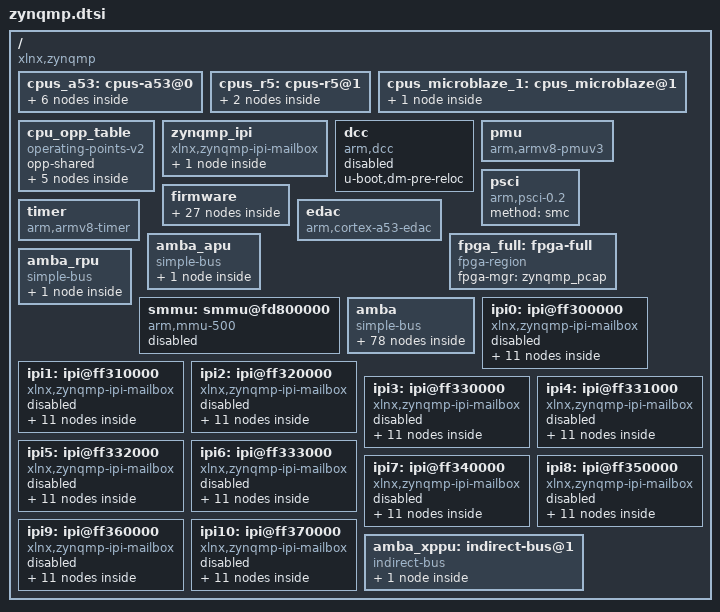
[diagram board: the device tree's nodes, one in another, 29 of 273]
// SPDX-License-Identifier: GPL-2.0+
/*
 * dts file for Xilinx ZynqMP
 *
 * (C) Copyright 2014 - 2021, Xilinx, Inc.
 *
 * Michal Simek <michal.simek@xilinx.com>
 *
 * This program is free software; you can redistribute it and/or
 * modify it under the terms of the GNU General Public License as
 * published by the Free Software Foundation; either version 2 of
 * the License, or (at your option) any later version.
 */

#include "include/dt-bindings/dma/xlnx-zynqmp-dpdma.h"
#include "include/dt-bindings/gpio/gpio.h"
#include "include/dt-bindings/power/xlnx-zynqmp-power.h"
#include "include/dt-bindings/reset/xlnx-zynqmp-resets.h"

/ {
	compatible = "xlnx,zynqmp";
	#address-cells = <2>;
	#size-cells = <2>;

	cpus_a53: cpus-a53@0 {
		#address-cells = <1>;
		#size-cells = <0>;

		a53_cpu0: cpu@0 {
			compatible = "arm,cortex-a53";
			device_type = "cpu";
			enable-method = "psci";
			operating-points-v2 = <&cpu_opp_table>;
			reg = <0x0>;
			cpu-idle-states = <&CPU_SLEEP_0>;
                        power-domains = <&zynqmp_firmware 0x2>;
		};

		a53_cpu1: cpu@1 {
			compatible = "arm,cortex-a53";
			device_type = "cpu";
			enable-method = "psci";
			reg = <0x1>;
			operating-points-v2 = <&cpu_opp_table>;
			cpu-idle-states = <&CPU_SLEEP_0>;
                        power-domains = <&zynqmp_firmware 0x3>;
		};

		a53_cpu2: cpu@2 {
			compatible = "arm,cortex-a53";
			device_type = "cpu";
			enable-method = "psci";
			reg = <0x2>;
			operating-points-v2 = <&cpu_opp_table>;
			cpu-idle-states = <&CPU_SLEEP_0>;
                        power-domains = <&zynqmp_firmware 0x4>;
		};

		a53_cpu3: cpu@3 {
			compatible = "arm,cortex-a53";
			device_type = "cpu";
			enable-method = "psci";
			reg = <0x3>;
			operating-points-v2 = <&cpu_opp_table>;
			cpu-idle-states = <&CPU_SLEEP_0>;
                        power-domains = <&zynqmp_firmware 0x5>;
		};


		idle-states {
			entry-method = "psci";

			CPU_SLEEP_0: cpu-sleep-0 {
				compatible = "arm,idle-state";
				arm,psci-suspend-param = <0x40000000>;
				local-timer-stop;
				entry-latency-us = <300>;
				exit-latency-us = <600>;
				min-residency-us = <10000>;
			};
		};
	};
	cpus_r5: cpus-r5@1 {
		#address-cells = <1>;
		#size-cells = <0>;

		r5_cpu0: cpu@0 {
			compatible = "arm,cortex-r5", "arm,armv8";
			device_type = "cpu";
			reg = <0x4>;
                        power-domains = <&zynqmp_firmware 0x7>;
		};

		r5_cpu1: cpu@1 {
			compatible = "arm,cortex-r5", "arm,armv8";
			device_type = "cpu";
			reg = <0x5>;
                        power-domains = <&zynqmp_firmware 0x8>;
		};
	};
	cpus_microblaze_1: cpus_microblaze@1 {
		#address-cells = <1>;
		#size-cells = <0>;

		ub1_cpu: cpu@0 {
			compatible = "pmu-microblaze";
			device_type = "cpu";
			reg = <0x6>;
			operating-points-v2 = <&cpu_opp_table>;
		};
	};
	cpu_opp_table: cpu_opp_table {
		compatible = "operating-points-v2";
		opp-shared;
		opp00 {
			opp-hz = /bits/ 64 <1199999988>;
			opp-microvolt = <1000000>;
			clock-latency-ns = <500000>;
		};
		opp01 {
			opp-hz = /bits/ 64 <599999994>;
			opp-microvolt = <1000000>;
			clock-latency-ns = <500000>;
		};
		opp02 {
			opp-hz = /bits/ 64 <399999996>;
			opp-microvolt = <1000000>;
			clock-latency-ns = <500000>;
		};
		opp03 {
			opp-hz = /bits/ 64 <299999997>;
			opp-microvolt = <1000000>;
			clock-latency-ns = <500000>;
		};
		opp04 {
			opp-hz = /bits/ 64 <180000000>;
			opp-microvolt = <1000000>;
			clock-latency-ns = <500000>;
		};
	};

	zynqmp_ipi: zynqmp_ipi {
		u-boot,dm-pre-reloc;
		compatible = "xlnx,zynqmp-ipi-mailbox";
		interrupt-parent = <&imux>;
		interrupts = <0 35 4>;
		xlnx,ipi-id = <0>;
		#address-cells = <2>;
		#size-cells = <2>;
		ranges;

		ipi_mailbox_pmu1: mailbox@ff990400 {
			u-boot,dm-pre-reloc;
			reg = <0x0 0xff9905c0 0x0 0x20>,
			      <0x0 0xff9905e0 0x0 0x20>,
			      <0x0 0xff990e80 0x0 0x20>,
			      <0x0 0xff990ea0 0x0 0x20>;
			reg-names = "local_request_region", "local_response_region",
				    "remote_request_region", "remote_response_region";
			#mbox-cells = <1>;
			xlnx,ipi-id = <4>;
		};
	};

	dcc: dcc {
		compatible = "arm,dcc";
		status = "disabled";
		u-boot,dm-pre-reloc;
	};

	pmu {
		compatible = "arm,armv8-pmuv3";
		interrupt-parent = <&imux>;
		interrupts = <0 143 4>,
			     <0 144 4>,
			     <0 145 4>,
			     <0 146 4>;
	};

	psci {
		compatible = "arm,psci-0.2";
		method = "smc";
	};

	firmware {
		zynqmp_firmware: zynqmp-firmware {
			compatible = "xlnx,zynqmp-firmware";
			u-boot,dm-pre-reloc;
			method = "smc";
			#power-domain-cells = <0x1>;

			zynqmp_power: zynqmp-power {
				u-boot,dm-pre-reloc;
				compatible = "xlnx,zynqmp-power";
				interrupt-parent = <&imux>;
				interrupts = <0 35 4>;
				mboxes = <&ipi_mailbox_pmu1 0>,
                                         <&ipi_mailbox_pmu1 1>;
				mbox-names = "tx", "rx";
			};

                       nvmem_firmware {
                               compatible = "xlnx,zynqmp-nvmem-fw";
                               #address-cells = <1>;
                               #size-cells = <1>;

                               soc_revision: soc_revision@0 {
                                       reg = <0x0 0x4>;
                               };
                               /* efuse access */
                               efuse_dna: efuse_dna@c {
                                       reg = <0xc 0xc>;
                               };
                               efuse_usr0: efuse_usr0@20 {
                                       reg = <0x20 0x4>;
                               };
                               efuse_usr1: efuse_usr1@24 {
                                       reg = <0x24 0x4>;
                               };
                               efuse_usr2: efuse_usr2@28 {
                                       reg = <0x28 0x4>;
                               };
                               efuse_usr3: efuse_usr3@2c {
                                       reg = <0x2c 0x4>;
                               };
                               efuse_usr4: efuse_usr4@30 {
                                       reg = <0x30 0x4>;
                               };
                               efuse_usr5: efuse_usr5@34 {
                                       reg = <0x34 0x4>;
                               };
                               efuse_usr6: efuse_usr6@38 {
                                       reg = <0x38 0x4>;
                               };
                               efuse_usr7: efuse_usr7@3c {
                                       reg = <0x3c 0x4>;
                               };
                               efuse_miscusr: efuse_miscusr@40 {
                                       reg = <0x40 0x4>;
                               };
                               efuse_chash: efuse_chash@50 {
                                       reg = <0x50 0x4>;
                               };
                               efuse_pufmisc: efuse_pufmisc@54 {
                                       reg = <0x54 0x4>;
                               };
                               efuse_sec: efuse_sec@58 {
                                       reg = <0x58 0x4>;
                               };
                               efuse_spkid: efuse_spkid@5c {
                                       reg = <0x5c 0x4>;
                               };
                               efuse_ppk0hash: efuse_ppk0hash@a0 {
                                       reg = <0xa0 0x30>;
                               };
                               efuse_ppk1hash: efuse_ppk1hash@d0 {
                                       reg = <0xd0 0x30>;
                               };
                       };

                       zynqmp_pcap: pcap {
                               compatible = "xlnx,zynqmp-pcap-fpga";
                               clock-names = "ref_clk";
                       };

                       xlnx_aes: zynqmp-aes {
                               compatible = "xlnx,zynqmp-aes";
                       };

			zynqmp_reset: reset-controller {
				compatible = "xlnx,zynqmp-reset";
				#reset-cells = <1>;
			};

			pinctrl0: pinctrl {
				compatible = "xlnx,zynqmp-pinctrl";
				status = "disabled";
			};

                       xlnx_keccak_384: sha384 {
                               compatible = "xlnx,zynqmp-keccak-384";
                       };

                       xlnx_rsa: zynqmp-rsa {
                               compatible = "xlnx,zynqmp-rsa";
                       };

                       modepin_gpio: gpio {
                               compatible = "xlnx,zynqmp-gpio-modepin";
                               gpio-controller;
                               #gpio-cells = <2>;
                       };
		};
	};

	timer {
		compatible = "arm,armv8-timer";
		interrupt-parent = <&imux>;
		interrupts = <1 13 0xf08>,
			     <1 14 0xf08>,
			     <1 11 0xf08>,
			     <1 10 0xf08>;
	};

	edac {
		compatible = "arm,cortex-a53-edac";
	};

	fpga_full: fpga-full {
		compatible = "fpga-region";
		fpga-mgr = <&zynqmp_pcap>;
		#address-cells = <2>;
		#size-cells = <2>;
		ranges;
	};


	amba_apu: amba_apu {
		compatible = "simple-bus";
		#address-cells = <2>;
		#size-cells = <1>;
		ranges = <0 0 0 0 0xffffffff>;

		gic_a53: interrupt-controller@f9010000 {
			compatible = "arm,gic-400";
			#interrupt-cells = <3>;
			reg = <0x0 0xf9010000 0x10000>,
			      <0x0 0xf9020000 0x20000>,
			      <0x0 0xf9040000 0x20000>,
			      <0x0 0xf9060000 0x20000>;
			interrupt-controller;
			interrupt-parent = <&gic_a53>;
			interrupts = <1 9 0xf04>;
			status = "disabled";
		};
	};

	amba_rpu: amba_rpu {
		compatible = "simple-bus";
		#address-cells = <2>;
		#size-cells = <1>;
		gic_r5: interrupt-controller@f9000000 {
			compatible = "arm,gic-400";
			#interrupt-cells = <3>;
			reg = <0x0 0xf9000000 0x10000>,
			      <0x0 0xf9001000 0x10000>;
			interrupt-controller;
			interrupt-parent = <&gic_r5>;
			interrupts = <1 9 0xf04>;
			status = "disabled";
		};
	};

	smmu: smmu@fd800000 {
		compatible = "arm,mmu-500";
		reg = <0x0 0xfd800000 0x0 0x20000>;
		#iommu-cells = <1>;
		status = "disabled";
		#global-interrupts = <1>;
		interrupt-parent = <&imux>;
		interrupts = <0 155 4>,
			<0 155 4>, <0 155 4>, <0 155 4>, <0 155 4>,
			<0 155 4>, <0 155 4>, <0 155 4>, <0 155 4>,
			<0 155 4>, <0 155 4>, <0 155 4>, <0 155 4>,
			<0 155 4>, <0 155 4>, <0 155 4>, <0 155 4>;
	};

	amba: amba {
		compatible = "simple-bus";
		u-boot,dm-pre-reloc;
		#address-cells = <2>;
		#size-cells = <2>;
		ranges;
		interrupt-parent = <&imux>;

		/* Proxy Interrupt Controller */
		imux: interrupt-multiplex {
			compatible = "interrupt-multiplex";
			#address-cells = <0x0>;
			#interrupt-cells = <3>;
			interrupt-controller;
			interrupt-parent = <&gic_a53>, <&gic_r5>;
			/* mask for address cells, mask for interrupt cells of the children */
			interrupt-map-mask = <0x0 0xffff 0x0>;
			/* 1:1 mapping of all interrupts to gic_a53 and gic_r5 */
			/* child address cells, child interrupt cells, parent, parent interrupt cells */
			interrupt-map = <0x0 0x17 0x0 &gic_a53 0x0 0x17 0x1>,
			                <0x0 0x18 0x0 &gic_a53 0x0 0x18 0x1>,
			                <0x0 0x7b 0x0 &gic_a53 0x0 0x7b 0x4>,
			                <0x0 0x56 0x0 &gic_a53 0x0 0x56 0x4>,
			                <0x0 0x7c 0x0 &gic_a53 0x0 0x7c 0x4>,
			                <0x0 0x7d 0x0 &gic_a53 0x0 0x7d 0x4>,
			                <0x0 0x7e 0x0 &gic_a53 0x0 0x8e 0x4>,
			                <0x0 0x7f 0x0 &gic_a53 0x0 0x7f 0x4>,
			                <0x0 0x80 0x0 &gic_a53 0x0 0x80 0x4>,
			                <0x0 0x81 0x0 &gic_a53 0x0 0x81 0x4>,
			                <0x0 0x82 0x0 &gic_a53 0x0 0x82 0x4>,
			                <0x0 0x83 0x0 &gic_a53 0x0 0x83 0x4>,
			                <0x0 0x84 0x0 &gic_a53 0x0 0x84 0x4>,
			                <0x0 0x4d 0x0 &gic_a53 0x0 0x4d 0x4>,
			                <0x0 0x4e 0x0 &gic_a53 0x0 0x4e 0x4>,
			                <0x0 0x4f 0x0 &gic_a53 0x0 0x4f 0x4>,
			                <0x0 0x50 0x0 &gic_a53 0x0 0x50 0x4>,
			                <0x0 0x51 0x0 &gic_a53 0x0 0x51 0x4>,
			                <0x0 0x52 0x0 &gic_a53 0x0 0x52 0x4>,
			                <0x0 0x53 0x0 &gic_a53 0x0 0x53 0x4>,
			                <0x0 0x54 0x0 &gic_a53 0x0 0x54 0x4>,
			                <0x0 0x70 0x0 &gic_a53 0x0 0x70 0x4>,
			                <0x0 0xe 0x0 &gic_a53 0x0 0xe 0x4>,
			                <0x0 0x39 0x0 &gic_a53 0x0 0x39 0x4>,
			                <0x0 0x3b 0x0 &gic_a53 0x0 0x3b 0x4>,
			                <0x0 0x3d 0x0 &gic_a53 0x0 0x3d 0x4>,
			                <0x0 0x3f 0x0 &gic_a53 0x0 0x3f 0x4>,
			                <0x0 0x10 0x0 &gic_a53 0x0 0x10 0x4>,
			                <0x0 0x11 0x0 &gic_a53 0x0 0x11 0x4>,
			                <0x0 0x12 0x0 &gic_a53 0x0 0x12 0x4>,
			                <0x0 0xa 0x0 &gic_a53 0x0 0xa 0x4>,
			                <0x0 0x72 0x0 &gic_a53 0x0 0x72 0x4>,
			                <0x0 0x73 0x0 &gic_a53 0x0 0x73 0x4>,
			                <0x0 0x74 0x0 &gic_a53 0x0 0x74 0x1>,
			                <0x0 0x75 0x0 &gic_a53 0x0 0x75 0x1>,
			                <0x0 0x76 0x0 &gic_a53 0x0 0x76 0x4>,
			                <0x0 0xf 0x0 &gic_a53 0x0 0xf 0x4>,
			                <0x0 0x1a 0x0 &gic_a53 0x0 0x1a 0x4>,
			                <0x0 0x1b 0x0 &gic_a53 0x0 0x1b 0x4>,
			                <0x0 0x85 0x0 &gic_a53 0x0 0x85 0x4>,
			                <0x0 0x30 0x0 &gic_a53 0x0 0x30 0x4>,
			                <0x0 0x31 0x0 &gic_a53 0x0 0x31 0x4>,
			                <0x0 0x13 0x0 &gic_a53 0x0 0x13 0x4>,
			                <0x0 0x14 0x0 &gic_a53 0x0 0x14 0x4>,
			                <0x0 0x24 0x0 &gic_a53 0x0 0x24 0x4>,
			                <0x0 0x25 0x0 &gic_a53 0x0 0x25 0x4>,
			                <0x0 0x26 0x0 &gic_a53 0x0 0x26 0x4>,
			                <0x0 0x27 0x0 &gic_a53 0x0 0x27 0x4>,
			                <0x0 0x28 0x0 &gic_a53 0x0 0x28 0x4>,
			                <0x0 0x29 0x0 &gic_a53 0x0 0x29 0x4>,
			                <0x0 0x2a 0x0 &gic_a53 0x0 0x2a 0x4>,
			                <0x0 0x2b 0x0 &gic_a53 0x0 0x2b 0x4>,
			                <0x0 0x2c 0x0 &gic_a53 0x0 0x2c 0x4>,
			                <0x0 0x2d 0x0 &gic_a53 0x0 0x2d 0x4>,
			                <0x0 0x2e 0x0 &gic_a53 0x0 0x2e 0x4>,
			                <0x0 0x2f 0x0 &gic_a53 0x0 0x2f 0x4>,
			                <0x0 0x15 0x0 &gic_a53 0x0 0x15 0x4>,
			                <0x0 0x16 0x0 &gic_a53 0x0 0x16 0x4>,
			                <0x0 0x41 0x0 &gic_a53 0x0 0x41 0x4>,
			                <0x0 0x45 0x0 &gic_a53 0x0 0x45 0x4>,
			                <0x0 0x4b 0x0 &gic_a53 0x0 0x4b 0x4>,
			                <0x0 0x46 0x0 &gic_a53 0x0 0x46 0x4>,
			                <0x0 0x4a 0x0 &gic_a53 0x0 0x4a 0x4>,
			                <0x0 0x4c 0x0 &gic_a53 0x0 0x4c 0x4>,
			                <0x0 0x35 0x0 &gic_a53 0x0 0x35 0x4>,
			                <0x0 0x71 0x0 &gic_a53 0x0 0x71 0x4>,
			                <0x0 0x77 0x0 &gic_a53 0x0 0x77 0x4>,
			                <0x0 0x1d 0x0 &gic_a53 0x0 0x1d 0x4>,
			                <0x0 0x1e 0x0 &gic_a53 0x0 0x1e 0x4>,
			                <0x0 0x1f 0x0 &gic_a53 0x0 0x1f 0x4>,
			                <0x0 0x20 0x0 &gic_a53 0x0 0x20 0x4>,
			                <0x0 0x21 0x0 &gic_a53 0x0 0x21 0x4>,
			                <0x0 0x22 0x0 &gic_a53 0x0 0x22 0x4>,
			                <0x0 0x23 0x0 &gic_a53 0x0 0x23 0x4>,
			                <0x0 0x7a 0x0 &gic_a53 0x0 0x7a 0x4>,
					<0x0 0x17 0x0 &gic_r5 0x0 0x17 0x1>,
			                <0x0 0x18 0x0 &gic_r5 0x0 0x18 0x1>,
			                <0x0 0x7b 0x0 &gic_r5 0x0 0x7b 0x4>,
			                <0x0 0x56 0x0 &gic_r5 0x0 0x56 0x4>,
			                <0x0 0x7c 0x0 &gic_r5 0x0 0x7c 0x4>,
			                <0x0 0x7d 0x0 &gic_r5 0x0 0x7d 0x4>,
			                <0x0 0x7e 0x0 &gic_r5 0x0 0x8e 0x4>,
			                <0x0 0x7f 0x0 &gic_r5 0x0 0x7f 0x4>,
			                <0x0 0x80 0x0 &gic_r5 0x0 0x80 0x4>,
			                <0x0 0x81 0x0 &gic_r5 0x0 0x81 0x4>,
			                <0x0 0x82 0x0 &gic_r5 0x0 0x82 0x4>,
			                <0x0 0x83 0x0 &gic_r5 0x0 0x83 0x4>,
			                <0x0 0x84 0x0 &gic_r5 0x0 0x84 0x4>,
			                <0x0 0x4d 0x0 &gic_r5 0x0 0x4d 0x4>,
			                <0x0 0x4e 0x0 &gic_r5 0x0 0x4e 0x4>,
			                <0x0 0x4f 0x0 &gic_r5 0x0 0x4f 0x4>,
			                <0x0 0x50 0x0 &gic_r5 0x0 0x50 0x4>,
			                <0x0 0x51 0x0 &gic_r5 0x0 0x51 0x4>,
			                <0x0 0x52 0x0 &gic_r5 0x0 0x52 0x4>,
			                <0x0 0x53 0x0 &gic_r5 0x0 0x53 0x4>,
			                <0x0 0x54 0x0 &gic_r5 0x0 0x54 0x4>,
			                <0x0 0x70 0x0 &gic_r5 0x0 0x70 0x4>,
			                <0x0 0xe 0x0 &gic_r5 0x0 0xe 0x4>,
			                <0x0 0x39 0x0 &gic_r5 0x0 0x39 0x4>,
			                <0x0 0x3b 0x0 &gic_r5 0x0 0x3b 0x4>,
			                <0x0 0x3d 0x0 &gic_r5 0x0 0x3d 0x4>,
			                <0x0 0x3f 0x0 &gic_r5 0x0 0x3f 0x4>,
			                <0x0 0x10 0x0 &gic_r5 0x0 0x10 0x4>,
			                <0x0 0x11 0x0 &gic_r5 0x0 0x11 0x4>,
			                <0x0 0x12 0x0 &gic_r5 0x0 0x12 0x4>,
			                <0x0 0xa 0x0 &gic_r5 0x0 0xa 0x4>,
			                <0x0 0x72 0x0 &gic_r5 0x0 0x72 0x4>,
			                <0x0 0x73 0x0 &gic_r5 0x0 0x73 0x4>,
			                <0x0 0x74 0x0 &gic_r5 0x0 0x74 0x1>,
			                <0x0 0x75 0x0 &gic_r5 0x0 0x75 0x1>,
			                <0x0 0x76 0x0 &gic_r5 0x0 0x76 0x4>,
			                <0x0 0xf 0x0 &gic_r5 0x0 0xf 0x4>,
			                <0x0 0x1a 0x0 &gic_r5 0x0 0x1a 0x4>,
			                <0x0 0x1b 0x0 &gic_r5 0x0 0x1b 0x4>,
			                <0x0 0x85 0x0 &gic_r5 0x0 0x85 0x4>,
			                <0x0 0x30 0x0 &gic_r5 0x0 0x30 0x4>,
			                <0x0 0x31 0x0 &gic_r5 0x0 0x31 0x4>,
			                <0x0 0x13 0x0 &gic_r5 0x0 0x13 0x4>,
			                <0x0 0x14 0x0 &gic_r5 0x0 0x14 0x4>,
			                <0x0 0x24 0x0 &gic_r5 0x0 0x24 0x4>,
			                <0x0 0x25 0x0 &gic_r5 0x0 0x25 0x4>,
			                <0x0 0x26 0x0 &gic_r5 0x0 0x26 0x4>,
			                <0x0 0x27 0x0 &gic_r5 0x0 0x27 0x4>,
			                <0x0 0x28 0x0 &gic_r5 0x0 0x28 0x4>,
			                <0x0 0x29 0x0 &gic_r5 0x0 0x29 0x4>,
			                <0x0 0x2a 0x0 &gic_r5 0x0 0x2a 0x4>,
			                <0x0 0x2b 0x0 &gic_r5 0x0 0x2b 0x4>,
			                <0x0 0x2c 0x0 &gic_r5 0x0 0x2c 0x4>,
			                <0x0 0x2d 0x0 &gic_r5 0x0 0x2d 0x4>,
			                <0x0 0x2e 0x0 &gic_r5 0x0 0x2e 0x4>,
			                <0x0 0x2f 0x0 &gic_r5 0x0 0x2f 0x4>,
			                <0x0 0x15 0x0 &gic_r5 0x0 0x15 0x4>,
			                <0x0 0x16 0x0 &gic_r5 0x0 0x16 0x4>,
			                <0x0 0x41 0x0 &gic_r5 0x0 0x41 0x4>,
			                <0x0 0x45 0x0 &gic_r5 0x0 0x45 0x4>,
			                <0x0 0x4b 0x0 &gic_r5 0x0 0x4b 0x4>,
			                <0x0 0x46 0x0 &gic_r5 0x0 0x46 0x4>,
			                <0x0 0x4a 0x0 &gic_r5 0x0 0x4a 0x4>,
			                <0x0 0x4c 0x0 &gic_r5 0x0 0x4c 0x4>,
			                <0x0 0x35 0x0 &gic_r5 0x0 0x35 0x4>,
			                <0x0 0x71 0x0 &gic_r5 0x0 0x71 0x4>,
			                <0x0 0x77 0x0 &gic_r5 0x0 0x77 0x4>,
			                <0x0 0x1d 0x0 &gic_r5 0x0 0x1d 0x4>,
			                <0x0 0x1e 0x0 &gic_r5 0x0 0x1e 0x4>,
			                <0x0 0x1f 0x0 &gic_r5 0x0 0x1f 0x4>,
			                <0x0 0x20 0x0 &gic_r5 0x0 0x20 0x4>,
			                <0x0 0x21 0x0 &gic_r5 0x0 0x21 0x4>,
			                <0x0 0x22 0x0 &gic_r5 0x0 0x22 0x4>,
			                <0x0 0x23 0x0 &gic_r5 0x0 0x23 0x4>,
			                <0x0 0x7a 0x0 &gic_r5 0x0 0x7a 0x4>;

		};

		can0: can@ff060000 {
			compatible = "xlnx,zynq-can-1.0";
			status = "disabled";
			clock-names = "can_clk", "pclk";
			reg = <0x0 0xff060000 0x0 0x1000>;
			interrupts = <0 23 4>;
			interrupt-parent = <&imux>;
			tx-fifo-depth = <0x40>;
			rx-fifo-depth = <0x40>;
			power-domains = <&zynqmp_firmware 47>;
		};

		can1: can@ff070000 {
			compatible = "xlnx,zynq-can-1.0";
			status = "disabled";
			clock-names = "can_clk", "pclk";
			reg = <0x0 0xff070000 0x0 0x1000>;
			interrupts = <0 24 4>;
			interrupt-parent = <&imux>;
			tx-fifo-depth = <0x40>;
			rx-fifo-depth = <0x40>;
			power-domains = <&zynqmp_firmware 48>;
		};

		cci: cci@fd6e0000 {
			compatible = "arm,cci-400";
			reg = <0x0 0xfd6e0000 0x0 0x9000>;
			ranges = <0x0 0x0 0xfd6e0000 0x10000>;
			#address-cells = <1>;
			#size-cells = <1>;
			status = "disabled";

			pmu@9000 {
				compatible = "arm,cci-400-pmu,r1";
				reg = <0x9000 0x5000>;
				interrupt-parent = <&imux>;
				interrupts = <0 123 4>,
					     <0 123 4>,
					     <0 123 4>,
					     <0 123 4>,
					     <0 123 4>;
			};
		};

		/* GDMA */
		fpd_dma_chan1: dma-controller@fd500000 {
			status = "disabled";
			compatible = "xlnx,zynqmp-dma-1.0";
			reg = <0x0 0xfd500000 0x0 0x1000>;
			interrupt-parent = <&imux>;
			interrupts = <0 124 4>;
			clock-names = "clk_main", "clk_apb";
			xlnx,bus-width = <128>;
			#stream-id-cells = <1>;
			iommus = <&smmu 0x14e8>;
			power-domains = <&zynqmp_firmware 42>;
			#dma-cells = <1>;
		};

		fpd_dma_chan2: dma-controller@fd510000 {
			status = "disabled";
			compatible = "xlnx,zynqmp-dma-1.0";
			reg = <0x0 0xfd510000 0x0 0x1000>;
			interrupt-parent = <&imux>;
			interrupts = <0 125 4>;
			clock-names = "clk_main", "clk_apb";
			xlnx,bus-width = <128>;
			#stream-id-cells = <1>;
			iommus = <&smmu 0x14e9>;
			power-domains = <&zynqmp_firmware 42>;
			#dma-cells = <1>;
		};

		fpd_dma_chan3: dma-controller@fd520000 {
			status = "disabled";
			compatible = "xlnx,zynqmp-dma-1.0";
			reg = <0x0 0xfd520000 0x0 0x1000>;
			interrupt-parent = <&imux>;
			interrupts = <0 126 4>;
			clock-names = "clk_main", "clk_apb";
			xlnx,bus-width = <128>;
			#stream-id-cells = <1>;
			iommus = <&smmu 0x14ea>;
			power-domains = <&zynqmp_firmware 42>;
			#dma-cells = <1>;
		};

		fpd_dma_chan4: dma-controller@fd530000 {
			status = "disabled";
			compatible = "xlnx,zynqmp-dma-1.0";
			reg = <0x0 0xfd530000 0x0 0x1000>;
			interrupt-parent = <&imux>;
			interrupts = <0 127 4>;
			clock-names = "clk_main", "clk_apb";
			xlnx,bus-width = <128>;
			#stream-id-cells = <1>;
			iommus = <&smmu 0x14eb>;
			power-domains = <&zynqmp_firmware 42>;
			#dma-cells = <1>;
		};

		fpd_dma_chan5: dma-controller@fd540000 {
			status = "disabled";
			compatible = "xlnx,zynqmp-dma-1.0";
			reg = <0x0 0xfd540000 0x0 0x1000>;
			interrupt-parent = <&imux>;
			interrupts = <0 128 4>;
			clock-names = "clk_main", "clk_apb";
			xlnx,bus-width = <128>;
			#stream-id-cells = <1>;
			iommus = <&smmu 0x14ec>;
			power-domains = <&zynqmp_firmware 42>;
			#dma-cells = <1>;
		};

		fpd_dma_chan6: dma-controller@fd550000 {
			status = "disabled";
			compatible = "xlnx,zynqmp-dma-1.0";
			reg = <0x0 0xfd550000 0x0 0x1000>;
			interrupt-parent = <&imux>;
			interrupts = <0 129 4>;
			clock-names = "clk_main", "clk_apb";
			xlnx,bus-width = <128>;
			#stream-id-cells = <1>;
			iommus = <&smmu 0x14ed>;
			power-domains = <&zynqmp_firmware 42>;
			#dma-cells = <1>;
		};

		fpd_dma_chan7: dma-controller@fd560000 {
			status = "disabled";
			compatible = "xlnx,zynqmp-dma-1.0";
			reg = <0x0 0xfd560000 0x0 0x1000>;
			interrupt-parent = <&imux>;
			interrupts = <0 130 4>;
			clock-names = "clk_main", "clk_apb";
			xlnx,bus-width = <128>;
			#stream-id-cells = <1>;
			iommus = <&smmu 0x14ee>;
			power-domains = <&zynqmp_firmware 42>;
			#dma-cells = <1>;
		};

		fpd_dma_chan8: dma-controller@fd570000 {
			status = "disabled";
			compatible = "xlnx,zynqmp-dma-1.0";
			reg = <0x0 0xfd570000 0x0 0x1000>;
			interrupt-parent = <&imux>;
			interrupts = <0 131 4>;
			clock-names = "clk_main", "clk_apb";
			xlnx,bus-width = <128>;
			#stream-id-cells = <1>;
			iommus = <&smmu 0x14ef>;
			power-domains = <&zynqmp_firmware 42>;
			#dma-cells = <1>;
		};

		gpu: gpu@fd4b0000 {
			status = "disabled";
			compatible = "arm,mali-400", "arm,mali-utgard";
			reg = <0x0 0xfd4b0000 0x0 0x10000>;
			interrupt-parent = <&imux>;
			interrupts = <0 132 4>, <0 132 4>, <0 132 4>, <0 132 4>, <0 132 4>, <0 132 4>;
			interrupt-names = "IRQGP", "IRQGPMMU", "IRQPP0", "IRQPPMMU0", "IRQPP1", "IRQPPMMU1";
			clock-names = "gpu", "gpu_pp0", "gpu_pp1";
			power-domains = <&zynqmp_firmware 58>;
		};

		/* LPDDMA default allows only secured access. inorder to enable
		 * These dma channels, Users should ensure that these dma
		 * Channels are allowed for non secure access.
		 */
		lpd_dma_chan1: dma-controller@ffa80000 {
			status = "disabled";
			compatible = "xlnx,zynqmp-dma-1.0";
			reg = <0x0 0xffa80000 0x0 0x1000>;
			interrupt-parent = <&imux>;
			interrupts = <0 77 4>;
			clock-names = "clk_main", "clk_apb";
			xlnx,bus-width = <64>;
			#stream-id-cells = <1>;
		/*	iommus = <&smmu 0x868>; */
			power-domains = <&zynqmp_firmware 43>;
			#dma-cells = <1>;
		};

		lpd_dma_chan2: dma-controller@ffa90000 {
			status = "disabled";
			compatible = "xlnx,zynqmp-dma-1.0";
			reg = <0x0 0xffa90000 0x0 0x1000>;
			interrupt-parent = <&imux>;
			interrupts = <0 78 4>;
			clock-names = "clk_main", "clk_apb";
			xlnx,bus-width = <64>;
			#stream-id-cells = <1>;
		/*	iommus = <&smmu 0x869>; */
			power-domains = <&zynqmp_firmware 43>;
			#dma-cells = <1>;
		};

		lpd_dma_chan3: dma-controller@ffaa0000 {
			status = "disabled";
			compatible = "xlnx,zynqmp-dma-1.0";
			reg = <0x0 0xffaa0000 0x0 0x1000>;
			interrupt-parent = <&imux>;
			interrupts = <0 79 4>;
			clock-names = "clk_main", "clk_apb";
			xlnx,bus-width = <64>;
			#stream-id-cells = <1>;
		/*	iommus = <&smmu 0x86a>; */
			power-domains = <&zynqmp_firmware 43>;
			#dma-cells = <1>;
		};

		lpd_dma_chan4: dma-controller@ffab0000 {
			status = "disabled";
			compatible = "xlnx,zynqmp-dma-1.0";
			reg = <0x0 0xffab0000 0x0 0x1000>;
			interrupt-parent = <&imux>;
			interrupts = <0 80 4>;
			clock-names = "clk_main", "clk_apb";
			xlnx,bus-width = <64>;
			#stream-id-cells = <1>;
		/*	iommus = <&smmu 0x86b>; */
			power-domains = <&zynqmp_firmware 43>;
			#dma-cells = <1>;
		};

		lpd_dma_chan5: dma-controller@ffac0000 {
			status = "disabled";
			compatible = "xlnx,zynqmp-dma-1.0";
			reg = <0x0 0xffac0000 0x0 0x1000>;
			interrupt-parent = <&imux>;
			interrupts = <0 81 4>;
			clock-names = "clk_main", "clk_apb";
			xlnx,bus-width = <64>;
			#stream-id-cells = <1>;
		/*	iommus = <&smmu 0x86c>; */
			power-domains = <&zynqmp_firmware 43>;
			#dma-cells = <1>;
		};

		lpd_dma_chan6: dma-controller@ffad0000 {
			status = "disabled";
			compatible = "xlnx,zynqmp-dma-1.0";
			reg = <0x0 0xffad0000 0x0 0x1000>;
			interrupt-parent = <&imux>;
			interrupts = <0 82 4>;
			clock-names = "clk_main", "clk_apb";
			xlnx,bus-width = <64>;
			#stream-id-cells = <1>;
		/*	iommus = <&smmu 0x86d>; */
			power-domains = <&zynqmp_firmware 43>;
			#dma-cells = <1>;
		};

		lpd_dma_chan7: dma-controller@ffae0000 {
			status = "disabled";
			compatible = "xlnx,zynqmp-dma-1.0";
			reg = <0x0 0xffae0000 0x0 0x1000>;
			interrupt-parent = <&imux>;
			interrupts = <0 83 4>;
			clock-names = "clk_main", "clk_apb";
			xlnx,bus-width = <64>;
			#stream-id-cells = <1>;
		/*	iommus = <&smmu 0x86e>; */
			power-domains = <&zynqmp_firmware 43>;
			#dma-cells = <1>;
		};

		lpd_dma_chan8: dma-controller@ffaf0000 {
			status = "disabled";
			compatible = "xlnx,zynqmp-dma-1.0";
			reg = <0x0 0xffaf0000 0x0 0x1000>;
			interrupt-parent = <&imux>;
			interrupts = <0 84 4>;
			clock-names = "clk_main", "clk_apb";
			xlnx,bus-width = <64>;
			#stream-id-cells = <1>;
		/*	iommus = <&smmu 0x86f>; */
			power-domains = <&zynqmp_firmware 43>;
			#dma-cells = <1>;
		};

		mc: memory-controller@fd070000 {
			compatible = "xlnx,zynqmp-ddrc-2.40a";
			reg = <0x0 0xfd070000 0x0 0x30000>;
			interrupt-parent = <&imux>;
			interrupts = <0 112 4>;
			status = "disabled";
		};

		nand0: nand-controller@ff100000 {
			compatible = "xlnx,zynqmp-nand-controller", "arasan,nfc-v3p10";
			status = "disabled";
			reg = <0x0 0xff100000 0x0 0x1000>;
			clock-names = "controller", "bus";
			interrupt-parent = <&imux>;
			interrupts = <0 14 4>;
			#address-cells = <1>;
			#size-cells = <0>;
			#stream-id-cells = <1>;
			iommus = <&smmu 0x872>;
			power-domains = <&zynqmp_firmware 44>;
		};

		gem0: ethernet@ff0b0000 {
			compatible = "cdns,zynqmp-gem", "cdns,gem";
			status = "disabled";
			interrupt-parent = <&imux>;
			interrupts = <0 57 4>, <0 57 4>;
			reg = <0x0 0xff0b0000 0x0 0x1000>;
			clock-names = "pclk", "hclk", "tx_clk", "rx_clk", "tsu_clk";
			#address-cells = <1>;
			#size-cells = <0>;
			#stream-id-cells = <1>;
			iommus = <&smmu 0x874>;
			power-domains = <&zynqmp_firmware 29>;
			resets = <&zynqmp_reset ZYNQMP_RESET_GEM0>;
		};

		gem1: ethernet@ff0c0000 {
			compatible = "cdns,zynqmp-gem", "cdns,gem";
			status = "disabled";
			interrupt-parent = <&imux>;
			interrupts = <0 59 4>, <0 59 4>;
			reg = <0x0 0xff0c0000 0x0 0x1000>;
			clock-names = "pclk", "hclk", "tx_clk","rx_clk", "tsu_clk";
			#address-cells = <1>;
			#size-cells = <0>;
			#stream-id-cells = <1>;
			iommus = <&smmu 0x875>;
			power-domains = <&zynqmp_firmware 30>;
			resets = <&zynqmp_reset ZYNQMP_RESET_GEM1>;
		};

		gem2: ethernet@ff0d0000 {
			compatible = "cdns,zynqmp-gem", "cdns,gem";
			status = "disabled";
			interrupt-parent = <&imux>;
			interrupts = <0 61 4>, <0 61 4>;
			reg = <0x0 0xff0d0000 0x0 0x1000>;
			clock-names = "pclk", "hclk", "tx_clk","rx_clk", "tsu_clk";
			#address-cells = <1>;
			#size-cells = <0>;
			#stream-id-cells = <1>;
			iommus = <&smmu 0x876>;
			power-domains = <&zynqmp_firmware 31>;
			resets = <&zynqmp_reset ZYNQMP_RESET_GEM2>;
		};

		gem3: ethernet@ff0e0000 {
			compatible = "cdns,zynqmp-gem", "cdns,gem";
			status = "disabled";
			interrupt-parent = <&imux>;
			interrupts = <0 63 4>, <0 63 4>;
			reg = <0x0 0xff0e0000 0x0 0x1000>;
			clock-names = "pclk", "hclk", "tx_clk", "rx_clk", "tsu_clk";
			#address-cells = <1>;
			#size-cells = <0>;
			#stream-id-cells = <1>;
			iommus = <&smmu 0x877>;
			power-domains = <&zynqmp_firmware 32>;
			resets = <&zynqmp_reset ZYNQMP_RESET_GEM3>;
		};

		gpio: gpio@ff0a0000 {
			compatible = "xlnx,zynqmp-gpio-1.0";
			status = "disabled";
			#gpio-cells = <0x2>;
			gpio-controller;
			interrupt-parent = <&imux>;
			interrupts = <0 16 4>;
			interrupt-controller;
			#interrupt-cells = <2>;
			reg = <0x0 0xff0a0000 0x0 0x1000>;
			power-domains = <&zynqmp_firmware 46>;
			calibration = <0x7FFF>;
		};

		i2c0: i2c@ff020000 {
			compatible = "cdns,i2c-r1p14";
			status = "disabled";
			interrupt-parent = <&imux>;
			interrupts = <0 17 4>;
			reg = <0x0 0xff020000 0x0 0x1000>;
			#address-cells = <1>;
			#size-cells = <0>;
			power-domains = <&zynqmp_firmware 37>;
		};

		i2c1: i2c@ff030000 {
			compatible = "cdns,i2c-r1p14";
			status = "disabled";
			interrupt-parent = <&imux>;
			interrupts = <0 18 4>;
			reg = <0x0 0xff030000 0x0 0x1000>;
			#address-cells = <1>;
			#size-cells = <0>;
			power-domains = <&zynqmp_firmware 38>;
		};

		ocm: memory-controller@ff960000 {
			compatible = "xlnx,zynqmp-ocmc-1.0";
			reg = <0x0 0xff960000 0x0 0x1000>;
			interrupt-parent = <&imux>;
			interrupts = <0 10 4>;
		};

		perf_monitor_ocm: perf-monitor@ffa00000 {
			compatible = "xlnx,axi-perf-monitor";
			reg = <0x0 0xffa00000 0x0 0x10000>;
			status = "disabled";
			interrupts = <0 25 4>;
			interrupt-parent = <&imux>;
			xlnx,enable-profile = <0>;
			xlnx,enable-trace = <0>;
			xlnx,num-monitor-slots = <1>;
			xlnx,enable-event-count = <1>;
			xlnx,enable-event-log = <1>;
			xlnx,have-sampled-metric-cnt = <1>;
			xlnx,num-of-counters = <8>;
			xlnx,metric-count-width = <32>;
			xlnx,metrics-sample-count-width = <32>;
			xlnx,global-count-width = <32>;
			xlnx,metric-count-scale = <1>;
		};

		perf_monitor_ddr: perf-monitor@fd0b0000 {
			compatible = "xlnx,axi-perf-monitor";
			reg = <0x0 0xfd0b0000 0x0 0x10000>;
			status = "disabled";
			interrupts = <0 123 4>;
			interrupt-parent = <&imux>;
			xlnx,enable-profile = <0>;
			xlnx,enable-trace = <0>;
			xlnx,num-monitor-slots = <6>;
			xlnx,enable-event-count = <1>;
			xlnx,enable-event-log = <0>;
			xlnx,have-sampled-metric-cnt = <1>;
			xlnx,num-of-counters = <10>;
			xlnx,metric-count-width = <32>;
			xlnx,metrics-sample-count-width = <32>;
			xlnx,global-count-width = <32>;
			xlnx,metric-count-scale = <1>;
		};

		perf_monitor_cci: perf-monitor@fd490000 {
			compatible = "xlnx,axi-perf-monitor";
			reg = <0x0 0xfd490000 0x0 0x10000>;
			status = "disabled";
			interrupts = <0 123 4>;
			interrupt-parent = <&imux>;
			xlnx,enable-profile = <0>;
			xlnx,enable-trace = <0>;
			xlnx,num-monitor-slots = <1>;
			xlnx,enable-event-count = <1>;
			xlnx,enable-event-log = <0>;
			xlnx,have-sampled-metric-cnt = <1>;
			xlnx,num-of-counters = <8>;
			xlnx,metric-count-width = <32>;
			xlnx,metrics-sample-count-width = <32>;
			xlnx,global-count-width = <32>;
			xlnx,metric-count-scale = <1>;
		};

		perf_monitor_lpd: perf-monitor@ffa10000 {
			compatible = "xlnx,axi-perf-monitor";
			reg = <0x0 0xffa10000 0x0 0x10000>;
			status = "disabled";
			interrupts = <0 25 4>;
			interrupt-parent = <&imux>;
			xlnx,enable-profile = <0>;
			xlnx,enable-trace = <0>;
			xlnx,num-monitor-slots = <1>;
			xlnx,enable-event-count = <1>;
			xlnx,enable-event-log = <1>;
			xlnx,have-sampled-metric-cnt = <1>;
			xlnx,num-of-counters = <8>;
			xlnx,metric-count-width = <32>;
			xlnx,metrics-sample-count-width = <32>;
			xlnx,global-count-width = <32>;
			xlnx,metric-count-scale = <1>;
		};

		pcie: pcie@fd0e0000 {
			compatible = "xlnx,nwl-pcie-2.11";
			status = "disabled";
			#address-cells = <3>;
			#size-cells = <2>;
			#interrupt-cells = <1>;
			msi-controller;
			device_type = "pci";
			interrupt-parent = <&imux>;
			interrupts = <0 118 4>,
				     <0 117 4>,
				     <0 116 4>,
				     <0 115 4>,	/* MSI_1 [63...32] */
				     <0 114 4>;	/* MSI_0 [31...0] */
			interrupt-names = "misc", "dummy", "intx",
					  "msi1", "msi0";
			msi-parent = <&pcie>;
			reg = <0x0 0xfd0e0000 0x0 0x1000>,
			      <0x0 0xfd480000 0x0 0x1000>,
			      <0x80 0x00000000 0x0 0x1000000>;
			reg-names = "breg", "pcireg", "cfg";
			ranges = <0x02000000 0x00000000 0xe0000000 0x00000000 0xe0000000 0x00000000 0x10000000	/* non-prefetchable memory */
				  0x43000000 0x00000006 0x00000000 0x00000006 0x00000000 0x00000002 0x00000000>;/* prefetchable memory */
			interrupt-map-mask = <0x0 0x0 0x0 0x7>;
			bus-range = <0x00 0xff>;
			interrupt-map = <0x0 0x0 0x0 0x1 &pcie_intc 0x1>,
					<0x0 0x0 0x0 0x2 &pcie_intc 0x2>,
					<0x0 0x0 0x0 0x3 &pcie_intc 0x3>,
					<0x0 0x0 0x0 0x4 &pcie_intc 0x4>;
			power-domains = <&zynqmp_firmware 59>;
			#stream-id-cells = <1>;
			iommus = <&smmu 0x4d0>;
			pcie_intc: legacy-interrupt-controller {
				interrupt-controller;
				#address-cells = <0>;
				#interrupt-cells = <1>;
			};
		};

		qspi: spi@ff0f0000 {
			u-boot,dm-pre-reloc;
			compatible = "xlnx,zynqmp-qspi-1.0";
			status = "disabled";
			clock-names = "ref_clk", "pclk";
			interrupts = <0 15 4>;
			interrupt-parent = <&imux>;
			num-cs = <1>;
			reg = <0x0 0xff0f0000 0x0 0x1000>,
			      <0x0 0xc0000000 0x0 0x8000000>;
			#address-cells = <1>;
			#size-cells = <0>;
			#stream-id-cells = <1>;
			iommus = <&smmu 0x873>;
			power-domains = <&zynqmp_firmware 45>;
		};

               psgtr: phy@fd400000 {
                       compatible = "xlnx,zynqmp-psgtr-v1.1";
                       status = "disabled";
                       reg = <0x0 0xfd400000 0x0 0x40000>,
                             <0x0 0xfd3d0000 0x0 0x1000>;
                       reg-names = "serdes", "siou";
                       #phy-cells = <4>;
               };

		rtc: rtc@ffa60000 {
			compatible = "xlnx,zynqmp-rtc";
			status = "disabled";
			reg = <0x0 0xffa60000 0x0 0x100>;
			interrupt-parent = <&imux>;
			interrupts = <0 26 4>, <0 27 4>;
			interrupt-names = "alarm", "sec";
			calibration = <0x8000>;
		};

		sata: ahci@fd0c0000 {
			compatible = "ceva,ahci-1v84";
			status = "disabled";
			reg = <0x0 0xfd0c0000 0x0 0x2000>;
			interrupt-parent = <&imux>;
			interrupts = <0 133 4>;
			power-domains = <&zynqmp_firmware 28>;
			resets = <&zynqmp_reset ZYNQMP_RESET_SATA>;
			#stream-id-cells = <4>;
		/*	iommus = <&smmu 0x4c0>, <&smmu 0x4c1>,
				 <&smmu 0x4c2>, <&smmu 0x4c3>;*/
		};

		sdhci0: mmc@ff160000 {
			u-boot,dm-pre-reloc;
			compatible = "xlnx,zynqmp-8.9a", "arasan,sdhci-8.9a";
			status = "disabled";
			interrupt-parent = <&imux>;
			interrupts = <0 48 4>;
			reg = <0x0 0xff160000 0x0 0x1000>;
			clock-names = "clk_xin", "clk_ahb";
			xlnx,device_id = <0>;
			#stream-id-cells = <1>;
			iommus = <&smmu 0x870>;
			power-domains = <&zynqmp_firmware 39>;
			nvmem-cells = <&soc_revision>;
			nvmem-cell-names = "soc_revision";
			#clock-cells = <1>;
			clock-output-names = "clk_out_sd0", "clk_in_sd0";
			resets = <&zynqmp_reset ZYNQMP_RESET_SDIO0>;
		};

		sdhci1: mmc@ff170000 {
			u-boot,dm-pre-reloc;
			compatible = "xlnx,zynqmp-8.9a", "arasan,sdhci-8.9a";
			status = "disabled";
			interrupt-parent = <&imux>;
			interrupts = <0 49 4>;
			reg = <0x0 0xff170000 0x0 0x1000>;
			clock-names = "clk_xin", "clk_ahb";
			xlnx,device_id = <1>;
			#stream-id-cells = <1>;
			iommus = <&smmu 0x871>;
			power-domains = <&zynqmp_firmware 40>;
			nvmem-cells = <&soc_revision>;
			nvmem-cell-names = "soc_revision";
			#clock-cells = <1>;
			clock-output-names = "clk_out_sd1", "clk_in_sd1";
			resets = <&zynqmp_reset ZYNQMP_RESET_SDIO1>;
		};

		spi0: spi@ff040000 {
			compatible = "cdns,spi-r1p6";
			status = "disabled";
			interrupt-parent = <&imux>;
			interrupts = <0 19 4>;
			reg = <0x0 0xff040000 0x0 0x1000>;
			clock-names = "ref_clk", "pclk";
			#address-cells = <1>;
			#size-cells = <0>;
			power-domains = <&zynqmp_firmware 35>;
		};

		spi1: spi@ff050000 {
			compatible = "cdns,spi-r1p6";
			status = "disabled";
			interrupt-parent = <&imux>;
			interrupts = <0 20 4>;
			reg = <0x0 0xff050000 0x0 0x1000>;
			clock-names = "ref_clk", "pclk";
			#address-cells = <1>;
			#size-cells = <0>;
			power-domains = <&zynqmp_firmware 36>;
		};

		ttc0: ttc@ff110000 {
			compatible = "cdns,ttc";
			status = "disabled";
			interrupt-parent = <&imux>;
			interrupts = <0 36 4>, <0 37 4>, <0 38 4>;
			reg = <0x0 0xff110000 0x0 0x1000>;
			timer-width = <32>;
			power-domains = <&zynqmp_firmware 24>;
		};

		ttc1: ttc@ff120000 {
			compatible = "cdns,ttc";
			status = "disabled";
			interrupt-parent = <&imux>;
			interrupts = <0 39 4>, <0 40 4>, <0 41 4>;
			reg = <0x0 0xff120000 0x0 0x1000>;
			timer-width = <32>;
			power-domains = <&zynqmp_firmware 25>;
		};

		ttc2: ttc@ff130000 {
			compatible = "cdns,ttc";
			status = "disabled";
			interrupt-parent = <&imux>;
			interrupts = <0 42 4>, <0 43 4>, <0 44 4>;
			reg = <0x0 0xff130000 0x0 0x1000>;
			timer-width = <32>;
			power-domains = <&zynqmp_firmware 26>;
		};

		ttc3: ttc@ff140000 {
			compatible = "cdns,ttc";
			status = "disabled";
			interrupt-parent = <&imux>;
			interrupts = <0 45 4>, <0 46 4>, <0 47 4>;
			reg = <0x0 0xff140000 0x0 0x1000>;
			timer-width = <32>;
			power-domains = <&zynqmp_firmware 27>;
		};

		uart0: serial@ff000000 {
			u-boot,dm-pre-reloc;
			compatible = "xlnx,zynqmp-uart", "cdns,uart-r1p12";
			status = "disabled";
			interrupt-parent = <&imux>;
			interrupts = <0 21 4>;
			reg = <0x0 0xff000000 0x0 0x1000>;
			clock-names = "uart_clk", "pclk";
			power-domains = <&zynqmp_firmware 33>;
		};

		uart1: serial@ff010000 {
			u-boot,dm-pre-reloc;
			compatible = "xlnx,zynqmp-uart", "cdns,uart-r1p12";
			status = "disabled";
			interrupt-parent = <&imux>;
			interrupts = <0 22 4>;
			reg = <0x0 0xff010000 0x0 0x1000>;
			clock-names = "uart_clk", "pclk";
			power-domains = <&zynqmp_firmware 34>;
		};

		usb0: usb0@ff9d0000 {
			#address-cells = <2>;
			#size-cells = <2>;
			status = "disabled";
			compatible = "xlnx,zynqmp-dwc3";
			reg = <0x0 0xff9d0000 0x0 0x100>;
			clock-names = "bus_clk", "ref_clk";
			power-domains = <&zynqmp_firmware 22>;
                       resets = <&zynqmp_reset ZYNQMP_RESET_USB0_CORERESET>,
                                <&zynqmp_reset ZYNQMP_RESET_USB0_HIBERRESET>,
                                <&zynqmp_reset ZYNQMP_RESET_USB0_APB>;
                       reset-names = "usb_crst", "usb_hibrst", "usb_apbrst";
			reset-gpios = <&modepin_gpio 1 GPIO_ACTIVE_LOW>;
			ranges;

			dwc3_0: usb@fe200000 {
				compatible = "snps,dwc3";
				status = "disabled";
				reg = <0x0 0xfe200000 0x0 0x40000>;
				interrupt-parent = <&imux>;
				interrupt-names = "dwc_usb3", "otg", "hiber";
				interrupts = <0 65 4>, <0 69 4>, <0 75 4>;
				#stream-id-cells = <1>;
				iommus = <&smmu 0x860>;
				snps,quirk-frame-length-adjustment = <0x20>;
				snps,refclk_fladj;
				snps,enable_guctl1_resume_quirk;
				snps,enable_guctl1_ipd_quirk;
				snps,xhci-stream-quirk;
				/* snps,enable-hibernation; */
			};
		};

		usb1: usb1@ff9e0000 {
			#address-cells = <2>;
			#size-cells = <2>;
			status = "disabled";
			compatible = "xlnx,zynqmp-dwc3";
			reg = <0x0 0xff9e0000 0x0 0x100>;
			clock-names = "bus_clk", "ref_clk";
			power-domains = <&zynqmp_firmware 23>;
                       resets = <&zynqmp_reset ZYNQMP_RESET_USB1_CORERESET>,
                                <&zynqmp_reset ZYNQMP_RESET_USB1_HIBERRESET>,
                                <&zynqmp_reset ZYNQMP_RESET_USB1_APB>;
                       reset-names = "usb_crst", "usb_hibrst", "usb_apbrst";
			ranges;

			dwc3_1: usb@fe300000 {
				compatible = "snps,dwc3";
				status = "disabled";
				reg = <0x0 0xfe300000 0x0 0x40000>;
				interrupt-parent = <&imux>;
				interrupt-names = "dwc_usb3", "otg", "hiber";
				interrupts = <0 70 4>, <0 74 4>, <0 76 4>;
				#stream-id-cells = <1>;
				iommus = <&smmu 0x861>;
				snps,quirk-frame-length-adjustment = <0x20>;
				snps,refclk_fladj;
				snps,enable_guctl1_resume_quirk;
				snps,enable_guctl1_ipd_quirk;
				snps,xhci-stream-quirk;
			};
		};

		watchdog0: watchdog@fd4d0000 {
			compatible = "cdns,wdt-r1p2";
			status = "disabled";
			interrupt-parent = <&imux>;
			interrupts = <0 113 1>;
			reg = <0x0 0xfd4d0000 0x0 0x1000>;
			timeout-sec = <60>;
			reset-on-timeout;
		};

		lpd_watchdog: watchdog@ff150000 {
			compatible = "cdns,wdt-r1p2";
			status = "disabled";
			interrupt-parent = <&imux>;
			interrupts = <0 52 1>;
			reg = <0x0 0xff150000 0x0 0x1000>;
			timeout-sec = <10>;
		};

		xilinx_ams: ams@ffa50000 {
			compatible = "xlnx,zynqmp-ams";
			status = "disabled";
			interrupt-parent = <&imux>;
			interrupts = <0 56 4>;
			interrupt-names = "ams-irq";
			reg = <0x0 0xffa50000 0x0 0x800>;
			reg-names = "ams-base";
			#address-cells = <2>;
			#size-cells = <2>;
			#io-channel-cells = <1>;
			ranges;

			ams_ps: ams_ps@ffa50800 {
				compatible = "xlnx,zynqmp-ams-ps";
				status = "disabled";
				reg = <0x0 0xffa50800 0x0 0x400>;
			};

			ams_pl: ams_pl@ffa50c00 {
				compatible = "xlnx,zynqmp-ams-pl";
				status = "disabled";
				reg = <0x0 0xffa50c00 0x0 0x400>;
			};
		};

		zynqmp_dpdma: dma-controller@fd4c0000 {
			compatible = "xlnx,zynqmp-dpdma";
			status = "disabled";
			reg = <0x0 0xfd4c0000 0x0 0x1000>;
			interrupts = <0 122 4>;
			interrupt-parent = <&imux>;
			clock-names = "axi_clk";
			power-domains = <&zynqmp_firmware 41>;
			dma-channels = <6>;
			#stream-id-cells = <1>;
			iommus = <&smmu 0xce4>;
			#dma-cells = <1>;
			dma-video0channel {
				compatible = "xlnx,video0";
			};
			dma-video1channel {
				compatible = "xlnx,video1";
			};
			dma-video2channel {
				compatible = "xlnx,video2";
			};
			dma-graphicschannel {
				compatible = "xlnx,graphics";
			};
			dma-audio0channel {
				compatible = "xlnx,audio0";
			};
			dma-audio1channel {
				compatible = "xlnx,audio1";
			};
		};

		zynqmp_dpaud_setting: dp_aud@fd4ac000 {
        		compatible = "xlnx,zynqmp-dpaud-setting", "syscon";
        		reg = <0x0 0xfd4ac000 0x0 0x1000>;
		};

		zynqmp_dpsub: display@fd4a0000 {
			u-boot,dm-pre-reloc;
			compatible = "xlnx,zynqmp-dpsub-1.7";
			status = "disabled";
			reg = <0x0 0xfd4a0000 0x0 0x1000>,
			      <0x0 0xfd4aa000 0x0 0x1000>,
			      <0x0 0xfd4ab000 0x0 0x1000>,
			      <0x0 0xfd4ac000 0x0 0x1000>;
			reg-names = "dp", "blend", "av_buf", "aud";
			xlnx,dpaud-reg = <&zynqmp_dpaud_setting>;
			interrupts = <0 119 4>;
			interrupt-parent = <&imux>;
			#stream-id-cells = <1>;
			iommus = <&smmu 0xce3>;
			clock-names = "dp_apb_clk", "dp_aud_clk", "dp_vtc_pixel_clk_in";
			power-domains = <&zynqmp_firmware 41>;

                       resets = <&zynqmp_reset ZYNQMP_RESET_DP>;
                       dma-names = "vid0", "vid1", "vid2", "gfx0";
                       dmas = <&zynqmp_dpdma ZYNQMP_DPDMA_VIDEO0>,
                               <&zynqmp_dpdma ZYNQMP_DPDMA_VIDEO1>,
                               <&zynqmp_dpdma ZYNQMP_DPDMA_VIDEO2>,
                               <&zynqmp_dpdma ZYNQMP_DPDMA_GRAPHICS>;

			/* dummy node to to indicate there's no child i2c device */
			i2c-bus {
			};

			zynqmp_dp_snd_codec0: zynqmp_dp_snd_codec0 {
				compatible = "xlnx,dp-snd-codec";
				clock-names = "aud_clk";
			};

			zynqmp_dp_snd_pcm0: zynqmp_dp_snd_pcm0 {
				compatible = "xlnx,dp-snd-pcm0";
				dmas = <&zynqmp_dpdma 4>;
				dma-names = "tx";
			};

			zynqmp_dp_snd_pcm1: zynqmp_dp_snd_pcm1 {
				compatible = "xlnx,dp-snd-pcm1";
				dmas = <&zynqmp_dpdma 5>;
				dma-names = "tx";
			};

			zynqmp_dp_snd_card0: zynqmp_dp_snd_card {
				compatible = "xlnx,dp-snd-card";
				xlnx,dp-snd-pcm = <&zynqmp_dp_snd_pcm0>,
						  <&zynqmp_dp_snd_pcm1>;
				xlnx,dp-snd-codec = <&zynqmp_dp_snd_codec0>;
			};
		};

		csuwdt_0: watchdog@ffcb0000 {
			compatible = "cdns,wdt-r1p2";
			status = "disabled";
			interrupt-parent = <&imux>;
			interrupts = <0 53 1>;
			reg = <0x0 0xffcb0000 0x0 0x1000>;
			timeout-sec = <60>;
			reset-on-timeout;
			xlnx,clock-freq = <99990005>;
		};

		coresight_0: coresight@fe800000 {
			compatible = "xlnx,coresight-1.0";
			status = "disabled";
			reg = <0x0 0xfe800000 0x0 0x10000>;
		};

		/* CSU DMA */

		csudma_0: dma@ffc80000 {
		       status = "disabled";
                       compatible = "xlnx,zynqmp-csudma-1.0";
                       interrupt-parent = <&imux>;
                       interrupts = <0 86 4>;
                       reg = <0x0 0xffc80000 0x0 0x40000>;
                };


	};

	ipi0: ipi@ff300000 {
                status = "disabled";
                compatible = "xlnx,zynqmp-ipi-mailbox";
                interrupt-parent = <&imux>;
                interrupts = <0 35 4>;
                reg = <0x0 0xff300000 0x0 0x20>;
                xlnx,ipi-bitmask = <0x1>;
                xlnx,ipi-id = <0>;
		xlnx,ipi-buf-index = <2>;
                #address-cells = <2>;
                #size-cells = <2>;
                xlnx,ipi-target-count = <7>;
                u-boot,dm-pre-reloc;
                ranges;
                ipi0_0: mailbox@0 {
                        xlnx,ipi-id = <0>;
			xlnx,ipi-buf-index = <2>;
                        xlnx,ipi-bitmask = <0x1>;
                };
                ipi0_1: mailbox@1 {
                        xlnx,ipi-id = <1>;
			xlnx,ipi-buf-index = <0>;
                        xlnx,ipi-bitmask = <0x100>;
			xlnx,ipi-req-msg-buf = <0xff990400>;
			xlnx,ipi-rsp-msg-buf = <0xff990420>;
                };
                ipi0_2: mailbox@2 {
                        xlnx,ipi-id = <2>;
			xlnx,ipi-buf-index = <1>;
                        xlnx,ipi-bitmask = <0x200>;
			xlnx,ipi-req-msg-buf = <0xff990440>;
			xlnx,ipi-rsp-msg-buf = <0xff990460>;
                };
                ipi0_3: mailbox@3 {
                        xlnx,ipi-id = <3>;
			xlnx,ipi-buf-index = <7>;
                        xlnx,ipi-bitmask = <0x10000>;
			xlnx,ipi-req-msg-buf = <0xff9905c0>;
			xlnx,ipi-rsp-msg-buf = <0xff9905e0>;
                };
                ipi0_4: mailbox@4 {
                        xlnx,ipi-id = <4>;
			xlnx,ipi-buf-index = <7>;
                        xlnx,ipi-bitmask = <0x20000>;
			xlnx,ipi-req-msg-buf = <0xff9905c0>;
			xlnx,ipi-rsp-msg-buf = <0xff9905e0>;
                };
                ipi0_5: mailbox@5 {
                        xlnx,ipi-id = <5>;
			xlnx,ipi-buf-index = <7>;
                        xlnx,ipi-bitmask = <0x40000>;
			xlnx,ipi-req-msg-buf = <0xff9905c0>;
			xlnx,ipi-rsp-msg-buf = <0xff9905e0>;
                };
                ipi0_6: mailbox@6 {
                        xlnx,ipi-id = <6>;
			xlnx,ipi-buf-index = <7>;
                        xlnx,ipi-bitmask = <0x80000>;
			xlnx,ipi-req-msg-buf = <0xff9905c0>;
			xlnx,ipi-rsp-msg-buf = <0xff9905e0>;
                };
                ipi0_7: mailbox@7 {
                        xlnx,ipi-id = <7>;
			xlnx,ipi-buf-index = <3>;
                        xlnx,ipi-bitmask = <0x1000000>;
			xlnx,ipi-req-msg-buf = <0xff9904c0>;
			xlnx,ipi-rsp-msg-buf = <0xff9904e0>;
                };
                ipi0_8: mailbox@8 {
                        xlnx,ipi-id = <8>;
			xlnx,ipi-buf-index = <4>;
                        xlnx,ipi-bitmask = <0x2000000>;
			xlnx,ipi-req-msg-buf = <0xff990500>;
			xlnx,ipi-rsp-msg-buf = <0xff990520>;
                };
                ipi0_9: mailbox@9 {
                        xlnx,ipi-id = <9>;
			xlnx,ipi-buf-index = <5>;
                        xlnx,ipi-bitmask = <0x4000000>;
			xlnx,ipi-req-msg-buf = <0xff990540>;
			xlnx,ipi-rsp-msg-buf = <0xff990560>;
                };
                ipi0_10: mailbox@10 {
                        xlnx,ipi-id = <10>;
			xlnx,ipi-buf-index = <6>;
                        xlnx,ipi-bitmask = <0x8000000>;
			xlnx,ipi-req-msg-buf = <0xff990580>;
			xlnx,ipi-rsp-msg-buf = <0xff9905a0>;
                };
        };

        ipi1: ipi@ff310000 {
                status = "disabled";
                compatible = "xlnx,zynqmp-ipi-mailbox";
                interrupt-parent = <&imux>;
                interrupts = <0 33 4>;
                reg = <0x0 0xff310000 0x0 0x20>;
                xlnx,ipi-bitmask = <0x100>;
                xlnx,ipi-id = <1>;
		xlnx,ipi-buf-index = <0>;
                #address-cells = <2>;
                #size-cells = <2>;
                xlnx,ipi-target-count = <7>;
                u-boot,dm-pre-reloc;
                ranges;
                ipi1_0: mailbox@0 {
                        xlnx,ipi-id = <0>;
			xlnx,ipi-buf-index = <2>;
                        xlnx,ipi-bitmask = <0x1>;
			xlnx,ipi-req-msg-buf = <0xff990080>;
			xlnx,ipi-rsp-msg-buf = <0xff9900a0>;
                };
                ipi1_1: mailbox@1 {
                        xlnx,ipi-id = <1>;
			xlnx,ipi-buf-index = <0>;
                        xlnx,ipi-bitmask = <0x100>;
			xlnx,ipi-req-msg-buf = <0xff990000>;
			xlnx,ipi-rsp-msg-buf = <0xff990020>;
                };
                ipi1_2: mailbox@2 {
                        xlnx,ipi-id = <2>;
			xlnx,ipi-buf-index = <1>;
                        xlnx,ipi-bitmask = <0x200>;
			xlnx,ipi-req-msg-buf = <0xff990040>;
			xlnx,ipi-rsp-msg-buf = <0xff990060>;
                };
                ipi1_3: mailbox@3 {
                        xlnx,ipi-id = <3>;
			xlnx,ipi-buf-index = <7>;
                        xlnx,ipi-bitmask = <0x10000>;
			xlnx,ipi-req-msg-buf = <0xff9901c0>;
			xlnx,ipi-rsp-msg-buf = <0xff9901e0>;
                };
                ipi1_4: mailbox@4 {
                        xlnx,ipi-id = <4>;
			xlnx,ipi-buf-index = <7>;
                        xlnx,ipi-bitmask = <0x20000>;
			xlnx,ipi-req-msg-buf = <0xff9901c0>;
			xlnx,ipi-rsp-msg-buf = <0xff9901e0>;
                };
                ipi1_5: mailbox@5 {
                        xlnx,ipi-id = <5>;
			xlnx,ipi-buf-index = <7>;
                        xlnx,ipi-bitmask = <0x40000>;
			xlnx,ipi-req-msg-buf = <0xff9901c0>;
			xlnx,ipi-rsp-msg-buf = <0xff9901e0>;
                };
                ipi1_6: mailbox@6 {
                        xlnx,ipi-id = <6>;
			xlnx,ipi-buf-index = <7>;
                        xlnx,ipi-bitmask = <0x80000>;
			xlnx,ipi-req-msg-buf = <0xff9901c0>;
			xlnx,ipi-rsp-msg-buf = <0xff9901e0>;
                };
                ipi1_7: mailbox@7 {
                        xlnx,ipi-id = <7>;
			xlnx,ipi-buf-index = <3>;
                        xlnx,ipi-bitmask = <0x1000000>;
			xlnx,ipi-req-msg-buf = <0xff9900c0>;
			xlnx,ipi-rsp-msg-buf = <0xff9900e0>;
                };
                ipi1_8: mailbox@8 {
                        xlnx,ipi-id = <8>;
			xlnx,ipi-buf-index = <4>;
                        xlnx,ipi-bitmask = <0x2000000>;
			xlnx,ipi-req-msg-buf = <0xff990100>;
			xlnx,ipi-rsp-msg-buf = <0xff990120>;
                };
                ipi1_9: mailbox@9 {
                        xlnx,ipi-id = <9>;
			xlnx,ipi-buf-index = <5>;
                        xlnx,ipi-bitmask = <0x4000000>;
			xlnx,ipi-req-msg-buf = <0xff990140>;
			xlnx,ipi-rsp-msg-buf = <0xff990160>;
                };
                ipi1_10: mailbox@10 {
                        xlnx,ipi-id = <10>;
			xlnx,ipi-buf-index = <6>;
                        xlnx,ipi-bitmask = <0x8000000>;
			xlnx,ipi-req-msg-buf = <0xff990180>;
			xlnx,ipi-rsp-msg-buf = <0xff9901a0>;
                };
        };
        ipi2: ipi@ff320000 {
                status = "disabled";
                compatible = "xlnx,zynqmp-ipi-mailbox";
                interrupt-parent = <&imux>;
                interrupts = <0 34 4>;
                reg = <0x0 0xff320000 0x0 0x20>;
                xlnx,ipi-bitmask = <0x200>;
                xlnx,ipi-id = <2>;
		xlnx,ipi-buf-index = <1>;
                #address-cells = <2>;
                #size-cells = <2>;
                xlnx,ipi-target-count = <7>;
                u-boot,dm-pre-reloc;
                ranges;

                ipi2_0: mailbox@0 {
                        xlnx,ipi-id = <0>;
			xlnx,ipi-buf-index = <2>;
                        xlnx,ipi-bitmask = <0x1>;
			xlnx,ipi-req-msg-buf = <0xff990280>;
			xlnx,ipi-rsp-msg-buf = <0xff9902a0>;
                };
                ipi2_1: mailbox@1 {
                        xlnx,ipi-id = <1>;
			xlnx,ipi-buf-index = <0>;
                        xlnx,ipi-bitmask = <0x100>;
			xlnx,ipi-req-msg-buf = <0xff990200>;
			xlnx,ipi-rsp-msg-buf = <0xff990220>;
                };
                ipi2_2: mailbox@2 {
                        xlnx,ipi-id = <2>;
			xlnx,ipi-buf-index = <1>;
                        xlnx,ipi-bitmask = <0x200>;
			xlnx,ipi-req-msg-buf = <0xff990240>;
			xlnx,ipi-rsp-msg-buf = <0xff990260>;
                };
                ipi2_3: mailbox@3 {
                        xlnx,ipi-id = <3>;
			xlnx,ipi-buf-index = <7>;
                        xlnx,ipi-bitmask = <0x10000>;
			xlnx,ipi-req-msg-buf = <0xff9903c0>;
			xlnx,ipi-rsp-msg-buf = <0xff9903e0>;
                };
                ipi2_4: mailbox@4 {
                        xlnx,ipi-id = <4>;
			xlnx,ipi-buf-index = <7>;
                        xlnx,ipi-bitmask = <0x20000>;
			xlnx,ipi-req-msg-buf = <0xff9903c0>;
			xlnx,ipi-rsp-msg-buf = <0xff9903e0>;
                };
                ipi2_5: mailbox@5 {
                        xlnx,ipi-id = <5>;
			xlnx,ipi-buf-index = <7>;
                        xlnx,ipi-bitmask = <0x40000>;
			xlnx,ipi-req-msg-buf = <0xff9903c0>;
			xlnx,ipi-rsp-msg-buf = <0xff9903e0>;
                };
                ipi2_6: mailbox@6 {
                        xlnx,ipi-id = <6>;
			xlnx,ipi-buf-index = <7>;
                        xlnx,ipi-bitmask = <0x80000>;
			xlnx,ipi-req-msg-buf = <0xff9903c0>;
			xlnx,ipi-rsp-msg-buf = <0xff9903e0>;
                };
                ipi2_7: mailbox@7 {
                        xlnx,ipi-id = <7>;
			xlnx,ipi-buf-index = <3>;
                        xlnx,ipi-bitmask = <0x1000000>;
			xlnx,ipi-req-msg-buf = <0xff9902c0>;
			xlnx,ipi-rsp-msg-buf = <0xff9902e0>;
                };
                ipi2_8: mailbox@8 {
                        xlnx,ipi-id = <8>;
			xlnx,ipi-buf-index = <4>;
                        xlnx,ipi-bitmask = <0x2000000>;
			xlnx,ipi-req-msg-buf = <0xff990300>;
			xlnx,ipi-rsp-msg-buf = <0xff990320>;
                };
                ipi2_9: mailbox@9 {
                        xlnx,ipi-id = <9>;
			xlnx,ipi-buf-index = <5>;
                        xlnx,ipi-bitmask = <0x4000000>;
			xlnx,ipi-req-msg-buf = <0xff990340>;
			xlnx,ipi-rsp-msg-buf = <0xff990360>;
                };
                ipi2_10: mailbox@10 {
                        xlnx,ipi-id = <10>;
			xlnx,ipi-buf-index = <6>;
                        xlnx,ipi-bitmask = <0x8000000>;
			xlnx,ipi-req-msg-buf = <0xff990380>;
			xlnx,ipi-rsp-msg-buf = <0xff9903a0>;
                };
        };

        ipi3: ipi@ff330000 {
                status = "disabled";
                compatible = "xlnx,zynqmp-ipi-mailbox";
                reg = <0x0 0xff330000 0x0 0x20>;
                xlnx,ipi-bitmask = <0x10000>;
                xlnx,ipi-id = <3>;
		xlnx,ipi-buf-index = <7>;
                #address-cells = <2>;
                #size-cells = <2>;
                xlnx,ipi-target-count = <7>;
                u-boot,dm-pre-reloc;
                ranges;

                ipi3_0: mailbox@0 {
                        xlnx,ipi-id = <0>;
			xlnx,ipi-buf-index = <2>;
                        xlnx,ipi-bitmask = <0x1>;
			xlnx,ipi-req-msg-buf = <0xff990e80>;
			xlnx,ipi-rsp-msg-buf = <0xff990ea0>;
                };
                ipi3_1: mailbox@1 {
                        xlnx,ipi-id = <1>;
			xlnx,ipi-buf-index = <0>;
                        xlnx,ipi-bitmask = <0x100>;
			xlnx,ipi-req-msg-buf = <0xff990e00>;
			xlnx,ipi-rsp-msg-buf = <0xff990e20>;
                };
                ipi3_2: mailbox@2 {
                        xlnx,ipi-id = <2>;
			xlnx,ipi-buf-index = <1>;
                        xlnx,ipi-bitmask = <0x200>;
			xlnx,ipi-req-msg-buf = <0xff990e40>;
			xlnx,ipi-rsp-msg-buf = <0xff990e60>;
                };
                ipi3_3: mailbox@3 {
                        xlnx,ipi-id = <3>;
			xlnx,ipi-buf-index = <7>;
                        xlnx,ipi-bitmask = <0x10000>;
			xlnx,ipi-req-msg-buf = <0xff990fc0>;
			xlnx,ipi-rsp-msg-buf = <0xff990fe0>;
                };
                ipi3_4: mailbox@4 {
                        xlnx,ipi-id = <4>;
			xlnx,ipi-buf-index = <7>;
                        xlnx,ipi-bitmask = <0x20000>;
			xlnx,ipi-req-msg-buf = <0xff990fc0>;
			xlnx,ipi-rsp-msg-buf = <0xff990fe0>;
                };
                ipi3_5: mailbox@5 {
                        xlnx,ipi-id = <5>;
			xlnx,ipi-buf-index = <7>;
                        xlnx,ipi-bitmask = <0x40000>;
			xlnx,ipi-req-msg-buf = <0xff990fc0>;
			xlnx,ipi-rsp-msg-buf = <0xff990fe0>;
                };
                ipi3_6: mailbox@6 {
                        xlnx,ipi-id = <6>;
			xlnx,ipi-buf-index = <7>;
                        xlnx,ipi-bitmask = <0x80000>;
			xlnx,ipi-req-msg-buf = <0xff990fc0>;
			xlnx,ipi-rsp-msg-buf = <0xff990fe0>;
                };
                ipi3_7: mailbox@7 {
                        xlnx,ipi-id = <7>;
			xlnx,ipi-buf-index = <3>;
                        xlnx,ipi-bitmask = <0x1000000>;
			xlnx,ipi-req-msg-buf = <0xff990ec0>;
			xlnx,ipi-rsp-msg-buf = <0xff990ee0>;
                };
                ipi3_8: mailbox@8 {
                        xlnx,ipi-id = <8>;
			xlnx,ipi-buf-index = <4>;
                        xlnx,ipi-bitmask = <0x2000000>;
			xlnx,ipi-req-msg-buf = <0xff990f00>;
			xlnx,ipi-rsp-msg-buf = <0xff990f20>;
                };
                ipi3_9: mailbox@9 {
                        xlnx,ipi-id = <9>;
			xlnx,ipi-buf-index = <5>;
                        xlnx,ipi-bitmask = <0x4000000>;
			xlnx,ipi-req-msg-buf = <0xff990f40>;
			xlnx,ipi-rsp-msg-buf = <0xff990f60>;
                };
                ipi3_10: mailbox@10 {
                        xlnx,ipi-id = <10>;
			xlnx,ipi-buf-index = <6>;
                        xlnx,ipi-bitmask = <0x8000000>;
			xlnx,ipi-req-msg-buf = <0xff990f80>;
			xlnx,ipi-rsp-msg-buf = <0xff990fa0>;
                };
        };

        ipi4: ipi@ff331000 {
                status = "disabled";
                compatible = "xlnx,zynqmp-ipi-mailbox";
                reg = <0x0 0xff331000 0x0 0x20>;
                xlnx,ipi-bitmask = <0x20000U>;
                xlnx,ipi-id = <4>;
		xlnx,ipi-buf-index = <7>;
                #address-cells = <2>;
                #size-cells = <2>;
                xlnx,ipi-target-count = <7>;
                u-boot,dm-pre-reloc;
                ranges;

                ipi4_0: mailbox@0 {
                        xlnx,ipi-id = <0>;
			xlnx,ipi-buf-index = <2>;
                        xlnx,ipi-bitmask = <0x1>;
			xlnx,ipi-req-msg-buf = <0xff990e80>;
			xlnx,ipi-rsp-msg-buf = <0xff990ea0>;
                };
                ipi4_1: mailbox@1 {
                        xlnx,ipi-id = <1>;
			xlnx,ipi-buf-index = <0>;
                        xlnx,ipi-bitmask = <0x100>;
			xlnx,ipi-req-msg-buf = <0xff990e00>;
			xlnx,ipi-rsp-msg-buf = <0xff990e20>;
                };
                ipi4_2: mailbox@2 {
                        xlnx,ipi-id = <2>;
			xlnx,ipi-buf-index = <1>;
                        xlnx,ipi-bitmask = <0x200>;
			xlnx,ipi-req-msg-buf = <0xff990e40>;
			xlnx,ipi-rsp-msg-buf = <0xff990e60>;
                };
                ipi4_3: mailbox@3 {
                        xlnx,ipi-id = <3>;
			xlnx,ipi-buf-index = <7>;
                        xlnx,ipi-bitmask = <0x10000>;
			xlnx,ipi-req-msg-buf = <0xff990fc0>;
			xlnx,ipi-rsp-msg-buf = <0xff990fe0>;
                };
                ipi4_4: mailbox@4 {
                        xlnx,ipi-id = <4>;
			xlnx,ipi-buf-index = <7>;
                        xlnx,ipi-bitmask = <0x20000>;
			xlnx,ipi-req-msg-buf = <0xff990fc0>;
			xlnx,ipi-rsp-msg-buf = <0xff990fe0>;
                };
                ipi4_5: mailbox@5 {
                        xlnx,ipi-id = <5>;
			xlnx,ipi-buf-index = <7>;
                        xlnx,ipi-bitmask = <0x40000>;
			xlnx,ipi-req-msg-buf = <0xff990fc0>;
			xlnx,ipi-rsp-msg-buf = <0xff990fe0>;
                };
                ipi4_6: mailbox@6 {
                        xlnx,ipi-id = <6>;
			xlnx,ipi-buf-index = <7>;
                        xlnx,ipi-bitmask = <0x80000>;
			xlnx,ipi-req-msg-buf = <0xff990fc0>;
			xlnx,ipi-rsp-msg-buf = <0xff990fe0>;
                };
                ipi4_7: mailbox@7 {
                        xlnx,ipi-id = <7>;
			xlnx,ipi-buf-index = <3>;
                        xlnx,ipi-bitmask = <0x1000000>;
			xlnx,ipi-req-msg-buf = <0xff990ec0>;
			xlnx,ipi-rsp-msg-buf = <0xff990ee0>;
                };
                ipi4_8: mailbox@8 {
                        xlnx,ipi-id = <8>;
			xlnx,ipi-buf-index = <4>;
                        xlnx,ipi-bitmask = <0x2000000>;
			xlnx,ipi-req-msg-buf = <0xff990f00>;
			xlnx,ipi-rsp-msg-buf = <0xff990f20>;
                };
                ipi4_9: mailbox@9 {
                        xlnx,ipi-id = <9>;
			xlnx,ipi-buf-index = <5>;
                        xlnx,ipi-bitmask = <0x4000000>;
			xlnx,ipi-req-msg-buf = <0xff990f40>;
			xlnx,ipi-rsp-msg-buf = <0xff990f60>;
                };
                ipi4_10: mailbox@10 {
                        xlnx,ipi-id = <10>;
			xlnx,ipi-buf-index = <6>;
                        xlnx,ipi-bitmask = <0x8000000>;
			xlnx,ipi-req-msg-buf = <0xff990f80>;
			xlnx,ipi-rsp-msg-buf = <0xff990fa0>;
                };

                };

        ipi5: ipi@ff332000 {
                compatible = "xlnx,zynqmp-ipi-mailbox";
                status = "disabled";
                reg = <0x0 0xff332000 0x0 0x20>;
                xlnx,ipi-bitmask = <0x40000>;
                xlnx,ipi-id = <5>;
		xlnx,ipi-buf-index = <7>;
                #address-cells = <2>;
                #size-cells = <2>;
                xlnx,ipi-target-count = <7>;
                u-boot,dm-pre-reloc;
                ranges;
                ipi5_0: mailbox@0 {
                        xlnx,ipi-id = <0>;
			xlnx,ipi-buf-index = <2>;
                        xlnx,ipi-bitmask = <0x1>;
			xlnx,ipi-req-msg-buf = <0xff990e80>;
			xlnx,ipi-rsp-msg-buf = <0xff990ea0>;
                };
                ipi5_1: mailbox@1 {
                        xlnx,ipi-id = <1>;
			xlnx,ipi-buf-index = <0>;
                        xlnx,ipi-bitmask = <0x100>;
			xlnx,ipi-req-msg-buf = <0xff990e00>;
			xlnx,ipi-rsp-msg-buf = <0xff990e20>;
                };
                ipi5_2: mailbox@2 {
                        xlnx,ipi-id = <2>;
			xlnx,ipi-buf-index = <1>;
                        xlnx,ipi-bitmask = <0x200>;
			xlnx,ipi-req-msg-buf = <0xff990e40>;
			xlnx,ipi-rsp-msg-buf = <0xff990e60>;
                };
                ipi5_3: mailbox@3 {
                        xlnx,ipi-id = <3>;
			xlnx,ipi-buf-index = <7>;
                        xlnx,ipi-bitmask = <0x10000>;
			xlnx,ipi-req-msg-buf = <0xff990fc0>;
			xlnx,ipi-rsp-msg-buf = <0xff990fe0>;
                };
                ipi5_4: mailbox@4 {
                        xlnx,ipi-id = <4>;
			xlnx,ipi-buf-index = <7>;
                        xlnx,ipi-bitmask = <0x20000>;
			xlnx,ipi-req-msg-buf = <0xff990fc0>;
			xlnx,ipi-rsp-msg-buf = <0xff990fe0>;
                };
                ipi5_5: mailbox@5 {
                        xlnx,ipi-id = <5>;
			xlnx,ipi-buf-index = <7>;
                        xlnx,ipi-bitmask = <0x40000>;
			xlnx,ipi-req-msg-buf = <0xff990fc0>;
			xlnx,ipi-rsp-msg-buf = <0xff990fe0>;
                };
                ipi5_6: mailbox@6 {
                        xlnx,ipi-id = <6>;
			xlnx,ipi-buf-index = <7>;
                        xlnx,ipi-bitmask = <0x80000>;
			xlnx,ipi-req-msg-buf = <0xff990fc0>;
			xlnx,ipi-rsp-msg-buf = <0xff990fe0>;
                };
                ipi5_7: mailbox@7 {
                        xlnx,ipi-id = <7>;
			xlnx,ipi-buf-index = <3>;
                        xlnx,ipi-bitmask = <0x1000000>;
			xlnx,ipi-req-msg-buf = <0xff990ec0>;
			xlnx,ipi-rsp-msg-buf = <0xff990ee0>;
                };
                ipi5_8: mailbox@8 {
                        xlnx,ipi-id = <8>;
			xlnx,ipi-buf-index = <4>;
                        xlnx,ipi-bitmask = <0x2000000>;
			xlnx,ipi-req-msg-buf = <0xff990f00>;
			xlnx,ipi-rsp-msg-buf = <0xff990f20>;
                };
                ipi5_9: mailbox@9 {
                        xlnx,ipi-id = <9>;
			xlnx,ipi-buf-index = <5>;
                        xlnx,ipi-bitmask = <0x4000000>;
			xlnx,ipi-req-msg-buf = <0xff990f40>;
			xlnx,ipi-rsp-msg-buf = <0xff990f60>;
                };
                ipi5_10: mailbox@10 {
                        xlnx,ipi-id = <10>;
			xlnx,ipi-buf-index = <6>;
                        xlnx,ipi-bitmask = <0x8000000>;
			xlnx,ipi-req-msg-buf = <0xff990f80>;
			xlnx,ipi-rsp-msg-buf = <0xff990fa0>;
                };
        };

        ipi6: ipi@ff333000 {
                status = "disabled";
                compatible = "xlnx,zynqmp-ipi-mailbox";
                reg = <0x0 0xff333000 0x0 0x20>;
                xlnx,ipi-bitmask = <0x80000>;
                xlnx,ipi-id = <6>;
		xlnx,ipi-buf-index = <7>;
                #address-cells = <2>;
                #size-cells = <2>;
                xlnx,ipi-target-count = <7>;
                u-boot,dm-pre-reloc;
                ranges;

                ipi6_0: mailbox@0 {
                        xlnx,ipi-id = <0>;
			xlnx,ipi-buf-index = <2>;
                        xlnx,ipi-bitmask = <0x1>;
			xlnx,ipi-req-msg-buf = <0xff990e80>;
			xlnx,ipi-rsp-msg-buf = <0xff990ea0>;
                };
                ipi6_1: mailbox@1 {
                        xlnx,ipi-id = <1>;
			xlnx,ipi-buf-index = <0>;
                        xlnx,ipi-bitmask = <0x100>;
			xlnx,ipi-req-msg-buf = <0xff990e00>;
			xlnx,ipi-rsp-msg-buf = <0xff990e20>;
                };
                ipi6_2: mailbox@2 {
                        xlnx,ipi-id = <2>;
			xlnx,ipi-buf-index = <1>;
                        xlnx,ipi-bitmask = <0x200>;
			xlnx,ipi-req-msg-buf = <0xff990e40>;
			xlnx,ipi-rsp-msg-buf = <0xff990e60>;
                };
                ipi6_3: mailbox@3 {
                        xlnx,ipi-id = <3>;
			xlnx,ipi-buf-index = <7>;
                        xlnx,ipi-bitmask = <0x10000>;
			xlnx,ipi-req-msg-buf = <0xff990fc0>;
			xlnx,ipi-rsp-msg-buf = <0xff990fe0>;
                };
                ipi6_4: mailbox@4 {
                        xlnx,ipi-id = <4>;
			xlnx,ipi-buf-index = <7>;
                        xlnx,ipi-bitmask = <0x20000>;
			xlnx,ipi-req-msg-buf = <0xff990fc0>;
			xlnx,ipi-rsp-msg-buf = <0xff990fe0>;
                };
                ipi6_5: mailbox@5 {
                        xlnx,ipi-id = <5>;
			xlnx,ipi-buf-index = <7>;
                        xlnx,ipi-bitmask = <0x40000>;
			xlnx,ipi-req-msg-buf = <0xff990fc0>;
			xlnx,ipi-rsp-msg-buf = <0xff990fe0>;
                };
                ipi6_6: mailbox@6 {
                        xlnx,ipi-id = <6>;
			xlnx,ipi-buf-index = <7>;
                        xlnx,ipi-bitmask = <0x80000>;
			xlnx,ipi-req-msg-buf = <0xff990fc0>;
			xlnx,ipi-rsp-msg-buf = <0xff990fe0>;
                };
                ipi6_7: mailbox@7 {
                        xlnx,ipi-id = <7>;
			xlnx,ipi-buf-index = <3>;
                        xlnx,ipi-bitmask = <0x1000000>;
			xlnx,ipi-req-msg-buf = <0xff990ec0>;
			xlnx,ipi-rsp-msg-buf = <0xff990ee0>;
                };
                ipi6_8: mailbox@8 {
                        xlnx,ipi-id = <8>;
			xlnx,ipi-buf-index = <4>;
                        xlnx,ipi-bitmask = <0x2000000>;
			xlnx,ipi-req-msg-buf = <0xff990f00>;
			xlnx,ipi-rsp-msg-buf = <0xff990f20>;
                };
                ipi6_9: mailbox@9 {
                        xlnx,ipi-id = <9>;
			xlnx,ipi-buf-index = <5>;
                        xlnx,ipi-bitmask = <0x4000000>;
			xlnx,ipi-req-msg-buf = <0xff990f40>;
			xlnx,ipi-rsp-msg-buf = <0xff990f60>;
                };
                ipi6_10: mailbox@10 {
                        xlnx,ipi-id = <10>;
			xlnx,ipi-buf-index = <6>;
                        xlnx,ipi-bitmask = <0x8000000>;
			xlnx,ipi-req-msg-buf = <0xff990f80>;
			xlnx,ipi-rsp-msg-buf = <0xff990fa0>;
                };
        };

        ipi7: ipi@ff340000 {
                status = "disabled";
                compatible = "xlnx,zynqmp-ipi-mailbox";
                interrupt-parent = <&imux>;
                interrupts = <0 29 4>;
                reg = <0x0 0xff340000 0x0 0x20>;
                xlnx,ipi-bitmask = <0x1000000>;
                xlnx,ipi-id = <7>;
		xlnx,ipi-buf-index = <3>;
                #address-cells = <2>;
                #size-cells = <2>;
                xlnx,ipi-target-count = <7>;
                u-boot,dm-pre-reloc;
                ranges;

                ipi7_0: mailbox@0 {
                        xlnx,ipi-id = <0>;
			xlnx,ipi-buf-index = <2>;
                        xlnx,ipi-bitmask = <0x1>;
			xlnx,ipi-req-msg-buf = <0xff990680>;
			xlnx,ipi-rsp-msg-buf = <0xff9906a0>;
                };
                ipi7_1: mailbox@1 {
                        xlnx,ipi-id = <1>;
			xlnx,ipi-buf-index = <0>;
                        xlnx,ipi-bitmask = <0x100>;
			xlnx,ipi-req-msg-buf = <0xff990600>;
			xlnx,ipi-rsp-msg-buf = <0xff990620>;
                };
                ipi7_2: mailbox@2 {
                        xlnx,ipi-id = <2>;
			xlnx,ipi-buf-index = <1>;
                        xlnx,ipi-bitmask = <0x200>;
			xlnx,ipi-req-msg-buf = <0xff990640>;
			xlnx,ipi-rsp-msg-buf = <0xff990660>;
                };
                ipi7_3: mailbox@3 {
                        xlnx,ipi-id = <3>;
			xlnx,ipi-buf-index = <7>;
                        xlnx,ipi-bitmask = <0x10000>;
			xlnx,ipi-req-msg-buf = <0xff9907c0>;
			xlnx,ipi-rsp-msg-buf = <0xff9907e0>;
                };
                ipi7_4: mailbox@4 {
                        xlnx,ipi-id = <4>;
			xlnx,ipi-buf-index = <7>;
                        xlnx,ipi-bitmask = <0x20000>;
			xlnx,ipi-req-msg-buf = <0xff9907c0>;
			xlnx,ipi-rsp-msg-buf = <0xff9907e0>;
                };
                ipi7_5: mailbox@5 {
                        xlnx,ipi-id = <5>;
			xlnx,ipi-buf-index = <7>;
                        xlnx,ipi-bitmask = <0x40000>;
			xlnx,ipi-req-msg-buf = <0xff9907c0>;
			xlnx,ipi-rsp-msg-buf = <0xff9907e0>;
                };
                ipi7_6: mailbox@6 {
                        xlnx,ipi-id = <6>;
			xlnx,ipi-buf-index = <7>;
                        xlnx,ipi-bitmask = <0x80000>;
			xlnx,ipi-req-msg-buf = <0xff9907c0>;
			xlnx,ipi-rsp-msg-buf = <0xff9907e0>;
                };
                ipi7_7: mailbox@7 {
                        xlnx,ipi-id = <7>;
			xlnx,ipi-buf-index = <3>;
                        xlnx,ipi-bitmask = <0x1000000>;
			xlnx,ipi-req-msg-buf = <0xff9906c0>;
			xlnx,ipi-rsp-msg-buf = <0xff9906e0>;
                };
                ipi7_8: mailbox@8 {
                        xlnx,ipi-id = <8>;
			xlnx,ipi-buf-index = <4>;
                        xlnx,ipi-bitmask = <0x2000000>;
			xlnx,ipi-req-msg-buf = <0xff990700>;
			xlnx,ipi-rsp-msg-buf = <0xff990720>;
                };
                ipi7_9: mailbox@9 {
                        xlnx,ipi-id = <5>;
                        xlnx,ipi-bitmask = <0x4000000>;
			xlnx,ipi-req-msg-buf = <0xff990740>;
			xlnx,ipi-rsp-msg-buf = <0xff990760>;
                };
                ipi7_10: mailbox@10 {
                        xlnx,ipi-id = <10>;
			xlnx,ipi-buf-index = <6>;
                        xlnx,ipi-bitmask = <0x8000000>;
			xlnx,ipi-req-msg-buf = <0xff990780>;
			xlnx,ipi-rsp-msg-buf = <0xff9907a0>;
                };

        };

        ipi8: ipi@ff350000 {
                status = "disabled";
                compatible = "xlnx,zynqmp-ipi-mailbox";
                interrupt-parent = <&imux>;
                interrupts = <0 30 4>;
                reg = <0x0 0xff350000 0x0 0x20>;
                xlnx,ipi-bitmask = <0x2000000>;
                xlnx,ipi-id = <8>;
		xlnx,ipi-buf-index = <4>;
                #address-cells = <2>;
                #size-cells = <2>;
                xlnx,ipi-target-count = <7>;
                u-boot,dm-pre-reloc;
                ranges;
                ipi8_0: mailbox@0 {
                        xlnx,ipi-id = <0>;
			xlnx,ipi-buf-index = <2>;
                        xlnx,ipi-bitmask = <0x1>;
			xlnx,ipi-req-msg-buf = <0xff990880>;
			xlnx,ipi-rsp-msg-buf = <0xff9908a0>;
                };
                ipi8_1: mailbox@1 {
                        xlnx,ipi-id = <1>;
			xlnx,ipi-buf-index = <0>;
                        xlnx,ipi-bitmask = <0x100>;
			xlnx,ipi-req-msg-buf = <0xff990800>;
			xlnx,ipi-rsp-msg-buf = <0xff990820>;
                };
                ipi8_2: mailbox@2 {
                        xlnx,ipi-id = <2>;
			xlnx,ipi-buf-index = <1>;
                        xlnx,ipi-bitmask = <0x200>;
			xlnx,ipi-req-msg-buf = <0xff990840>;
			xlnx,ipi-rsp-msg-buf = <0xff990860>;
                };
                ipi8_3: mailbox@3 {
                        xlnx,ipi-id = <3>;
			xlnx,ipi-buf-index = <7>;
                        xlnx,ipi-bitmask = <0x10000>;
			xlnx,ipi-req-msg-buf = <0xff9909c0>;
			xlnx,ipi-rsp-msg-buf = <0xff9909e0>;
                };
                ipi8_4: mailbox@4 {
                        xlnx,ipi-id = <4>;
			xlnx,ipi-buf-index = <7>;
                        xlnx,ipi-bitmask = <0x20000>;
			xlnx,ipi-req-msg-buf = <0xff9909c0>;
			xlnx,ipi-rsp-msg-buf = <0xff9909e0>;
                };
                ipi8_5: mailbox@5 {
                        xlnx,ipi-id = <5>;
			xlnx,ipi-buf-index = <7>;
                        xlnx,ipi-bitmask = <0x40000>;
			xlnx,ipi-req-msg-buf = <0xff9909c0>;
			xlnx,ipi-rsp-msg-buf = <0xff9909e0>;
                };
                ipi8_6: mailbox@6 {
                        xlnx,ipi-id = <6>;
			xlnx,ipi-buf-index = <7>;
                        xlnx,ipi-bitmask = <0x80000>;
			xlnx,ipi-req-msg-buf = <0xff9909c0>;
			xlnx,ipi-rsp-msg-buf = <0xff9909e0>;
                };
                ipi8_7: mailbox@7 {
                        xlnx,ipi-id = <7>;
			xlnx,ipi-buf-index = <3>;
                        xlnx,ipi-bitmask = <0x1000000>;
			xlnx,ipi-req-msg-buf = <0xff9908c0>;
			xlnx,ipi-rsp-msg-buf = <0xff9908e0>;
                };
                ipi8_8: mailbox@8 {
                        xlnx,ipi-id = <8>;
			xlnx,ipi-buf-index = <4>;
                        xlnx,ipi-bitmask = <0x2000000>;
			xlnx,ipi-req-msg-buf = <0xff990900>;
			xlnx,ipi-rsp-msg-buf = <0xff990920>;
                };
                ipi8_9: mailbox@9 {
                        xlnx,ipi-id = <9>;
			xlnx,ipi-buf-index = <5>;
                        xlnx,ipi-bitmask = <0x4000000>;
			xlnx,ipi-req-msg-buf = <0xff990940>;
			xlnx,ipi-rsp-msg-buf = <0xff990960>;
                };
                ipi8_10: mailbox@10 {
                        xlnx,ipi-id = <10>;
			xlnx,ipi-buf-index = <6>;
                        xlnx,ipi-bitmask = <0x8000000>;
			xlnx,ipi-req-msg-buf = <0xff990980>;
			xlnx,ipi-rsp-msg-buf = <0xff9909a0>;
                };

        };

        ipi9: ipi@ff360000 {
                status = "disabled";
                compatible = "xlnx,zynqmp-ipi-mailbox";
                interrupt-parent = <&imux>;
                interrupts = <0 31 4>;
                reg = <0x0 0xff360000 0x0 0x20>;
                xlnx,ipi-bitmask = <0x4000000>;
                xlnx,ipi-id = <9>;
		xlnx,ipi-buf-index = <5>;
                #address-cells = <2>;
                #size-cells = <2>;
                xlnx,ipi-target-count = <7>;
                u-boot,dm-pre-reloc;
                ranges;
                ipi9_0: mailbox@0 {
                        xlnx,ipi-id = <0>;
			xlnx,ipi-buf-index = <2>;
                        xlnx,ipi-bitmask = <0x1>;
			xlnx,ipi-req-msg-buf = <0xff990a80>;
			xlnx,ipi-rsp-msg-buf = <0xff990aa0>;
                };
                ipi9_1: mailbox@1 {
                        xlnx,ipi-id = <1>;
			xlnx,ipi-buf-index = <0>;
                        xlnx,ipi-bitmask = <0x100>;
			xlnx,ipi-req-msg-buf = <0xff990a00>;
			xlnx,ipi-rsp-msg-buf = <0xff990a20>;
                };
                ipi9_2: mailbox@2 {
                        xlnx,ipi-id = <2>;
			xlnx,ipi-buf-index = <1>;
                        xlnx,ipi-bitmask = <0x200>;
			xlnx,ipi-req-msg-buf = <0xff990a40>;
			xlnx,ipi-rsp-msg-buf = <0xff990a60>;
                };
                ipi9_3: mailbox@3 {
                        xlnx,ipi-id = <3>;
			xlnx,ipi-buf-index = <7>;
                        xlnx,ipi-bitmask = <0x10000>;
			xlnx,ipi-req-msg-buf = <0xff990bc0>;
			xlnx,ipi-rsp-msg-buf = <0xff990be0>;
                };
                ipi9_4: mailbox@4 {
                        xlnx,ipi-id = <4>;
			xlnx,ipi-buf-index = <7>;
                        xlnx,ipi-bitmask = <0x20000>;
			xlnx,ipi-req-msg-buf = <0xff990bc0>;
			xlnx,ipi-rsp-msg-buf = <0xff990be0>;
                };
                ipi9_5: mailbox@5 {
                        xlnx,ipi-id = <5>;
			xlnx,ipi-buf-index = <7>;
                        xlnx,ipi-bitmask = <0x40000>;
			xlnx,ipi-req-msg-buf = <0xff990bc0>;
			xlnx,ipi-rsp-msg-buf = <0xff990be0>;
                };
                ipi9_6: mailbox@6 {
                        xlnx,ipi-id = <6>;
			xlnx,ipi-buf-index = <7>;
                        xlnx,ipi-bitmask = <0x80000>;
			xlnx,ipi-req-msg-buf = <0xff990bc0>;
			xlnx,ipi-rsp-msg-buf = <0xff990be0>;
                };
                ipi9_7: mailbox@7 {
                        xlnx,ipi-id = <7>;
			xlnx,ipi-buf-index = <3>;
                        xlnx,ipi-bitmask = <0x1000000>;
			xlnx,ipi-req-msg-buf = <0xff990ac0>;
			xlnx,ipi-rsp-msg-buf = <0xff990ae0>;
                };
                ipi9_8: mailbox@8 {
                        xlnx,ipi-id = <8>;
			xlnx,ipi-buf-index = <4>;
                        xlnx,ipi-bitmask = <0x2000000>;
			xlnx,ipi-req-msg-buf = <0xff990b00>;
			xlnx,ipi-rsp-msg-buf = <0xff990b20>;
                };
                ipi9_9: mailbox@9 {
                        xlnx,ipi-id = <9>;
			xlnx,ipi-buf-index = <5>;
                        xlnx,ipi-bitmask = <0x4000000>;
			xlnx,ipi-req-msg-buf = <0xff990b40>;
			xlnx,ipi-rsp-msg-buf = <0xff990b60>;
                };
                ipi9_10: mailbox@10 {
                        xlnx,ipi-id = <10>;
			xlnx,ipi-buf-index = <6>;
                        xlnx,ipi-bitmask = <0x8000000>;
			xlnx,ipi-req-msg-buf = <0xff990b80>;
			xlnx,ipi-rsp-msg-buf = <0xff990ba0>;
                };

        };

        ipi10: ipi@ff370000 {
                status = "disabled";
                compatible = "xlnx,zynqmp-ipi-mailbox";
                interrupt-parent = <&imux>;
                interrupts = <0 32 4>;
                reg = <0x0 0xff370000 0x0 0x20>;
                xlnx,ipi-bitmask = <0x8000000>;
                xlnx,ipi-id = <10>;
		xlnx,ipi-buf-index = <5>;
                #address-cells = <2>;
                #size-cells = <2>;
                xlnx,ipi-target-count = <7>;
                u-boot,dm-pre-reloc;
                ranges;
                ipi10_0: mailbox@0 {
                        xlnx,ipi-id = <0>;
			xlnx,ipi-buf-index = <2>;
                        xlnx,ipi-bitmask = <0x1>;
			xlnx,ipi-req-msg-buf = <0xff990c80>;
			xlnx,ipi-rsp-msg-buf = <0xff990ca0>;
                };
                ipi10_1: mailbox@1 {
                        xlnx,ipi-id = <1>;
			xlnx,ipi-buf-index = <0>;
                        xlnx,ipi-bitmask = <0x100>;
			xlnx,ipi-req-msg-buf = <0xff990c00>;
			xlnx,ipi-rsp-msg-buf = <0xff990c20>;
                };
                ipi10_2: mailbox@2 {
                        xlnx,ipi-id = <2>;
			xlnx,ipi-buf-index = <1>;
                        xlnx,ipi-bitmask = <0x200>;
			xlnx,ipi-req-msg-buf = <0xff990c40>;
			xlnx,ipi-rsp-msg-buf = <0xff990c60>;
                };
                ipi10_3: mailbox@3 {
                        xlnx,ipi-id = <3>;
			xlnx,ipi-buf-index = <7>;
                        xlnx,ipi-bitmask = <0x10000>;
			xlnx,ipi-req-msg-buf = <0xff990dc0>;
			xlnx,ipi-rsp-msg-buf = <0xff990de0>;
                };
                ipi10_4: mailbox@4 {
                        xlnx,ipi-id = <4>;
			xlnx,ipi-buf-index = <7>;
                        xlnx,ipi-bitmask = <0x20000>;
			xlnx,ipi-req-msg-buf = <0xff990dc0>;
			xlnx,ipi-rsp-msg-buf = <0xff990de0>;
                };
                ipi10_5: mailbox@5 {
                        xlnx,ipi-id = <5>;
			xlnx,ipi-buf-index = <7>;
                        xlnx,ipi-bitmask = <0x40000>;
			xlnx,ipi-req-msg-buf = <0xff990dc0>;
			xlnx,ipi-rsp-msg-buf = <0xff990de0>;
                };
                ipi10_6: mailbox@6 {
                        xlnx,ipi-id = <6>;
			xlnx,ipi-buf-index = <7>;
                        xlnx,ipi-bitmask = <0x80000>;
			xlnx,ipi-req-msg-buf = <0xff990dc0>;
			xlnx,ipi-rsp-msg-buf = <0xff990de0>;
                };
                ipi10_7: mailbox@7 {
                        xlnx,ipi-id = <7>;
			xlnx,ipi-buf-index = <3>;
                        xlnx,ipi-bitmask = <0x1000000>;
			xlnx,ipi-req-msg-buf = <0xff990cc0>;
			xlnx,ipi-rsp-msg-buf = <0xff990ce0>;
                };
                ipi10_8: mailbox@8 {
                        xlnx,ipi-id = <8>;
			xlnx,ipi-buf-index = <4>;
                        xlnx,ipi-bitmask = <0x2000000>;
			xlnx,ipi-req-msg-buf = <0xff990d00>;
			xlnx,ipi-rsp-msg-buf = <0xff990d20>;
                };
                ipi10_9: mailbox@9 {
                        xlnx,ipi-id = <9>;
			xlnx,ipi-buf-index = <5>;
                        xlnx,ipi-bitmask = <0x4000000>;
			xlnx,ipi-req-msg-buf = <0xff990d40>;
			xlnx,ipi-rsp-msg-buf = <0xff990d60>;
                };
                ipi10_10: mailbox@10 {
                        xlnx,ipi-id = <10>;
			xlnx,ipi-buf-index = <6>;
                        xlnx,ipi-bitmask = <0x8000000>;
			xlnx,ipi-req-msg-buf = <0xff990d80>;
			xlnx,ipi-rsp-msg-buf = <0xff990da0>;
                };
        };

        amba_xppu: indirect-bus@1 {
                compatible = "indirect-bus";
                #address-cells = <0x2>;
                #size-cells = <0x2>;
                lpd_xppu: xppu@ff980000 {
                        compatible = "xlnx,xppu";
                        #firewall-cells = <0x0>;
                        reg = <0x0 0xff980000 0x0 0x1000>;
                        status = "disabled";
                };
        };
};
